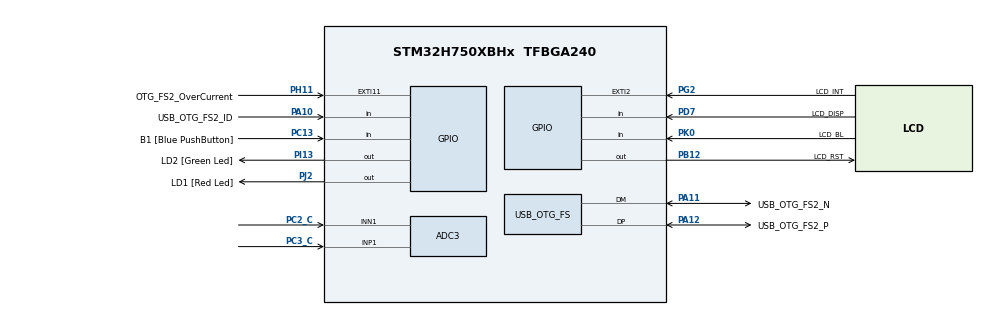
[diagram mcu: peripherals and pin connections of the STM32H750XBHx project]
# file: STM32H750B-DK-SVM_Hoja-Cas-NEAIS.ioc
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ADC3.Channel-0\#ChannelRegularConversion=ADC_CHANNEL_1
ADC3.NbrOfConversionFlag=1
ADC3.OffsetNumber-0\#ChannelRegularConversion=ADC_OFFSET_NONE
ADC3.Rank-0\#ChannelRegularConversion=1
ADC3.SamplingTime-0\#ChannelRegularConversion=ADC_SAMPLETIME_1CYCLE_5
ADC3.SingleDiff-0\#ChannelRegularConversion=ADC_DIFFERENTIAL_ENDED
Mcu.Family=STM32H7
Mcu.Name=STM32H750XBHx
Mcu.Package=TFBGA240
NVIC.OTG_FS_IRQn=true\:0\:0\:false\:false\:true\:false\:true\:true
NVIC.PriorityGroup=NVIC_PRIORITYGROUP_4
PA0_C.Signal=ADCx_INP0
PA1.GPIO_Label=MII_RX_CLK
PA1.Signal=ETH_RX_CLK
PA10.GPIO_Label=USB_OTG_FS2_ID
PA10.Signal=GPIO_Input
PA11.GPIO_Label=USB_OTG_FS2_N
PA11.Mode=Device_Only
PA11.Signal=USB_OTG_FS_DM
PA12.GPIO_Label=USB_OTG_FS2_P
PA12.Mode=Device_Only
PA12.Signal=USB_OTG_FS_DP
PA1_C.Signal=ADCx_INP1
PA2.GPIO_Label=MII_MDIO
PA2.Signal=ETH_MDIO
PA6.Signal=S_TIM13_CH1
PA7.GPIO_Label=MII_RX_DV
PA7.Signal=ETH_RX_DV
PA8.Signal=S_TIM1_CH1
PA9.GPIO_Label=VBUS_FS2
PA9.Signal=USB_OTG_FS_VBUS
PB0.GPIO_Label=MII_RX_D2
PB0.Signal=ETH_RXD2
PB1.GPIO_Label=MII_RX_D3
PB1.Signal=ETH_RXD3
PB10.GPIO_Label=VCP_TX
PB10.Signal=USART3_TX
PB11.GPIO_Label=VCP_RX
PB11.Signal=USART3_RX
PB12.GPIO_Label=LCD_RST
PB12.Signal=GPIO_Output
PB13.GPIO_Label=FDCAN2_TX
PB13.Signal=FDCAN2_TX
PB15.Signal=SPI2_MOSI
PB4\ (NJTRST).Signal=SPI2_NSS
PB5.GPIO_Label=FDCAN2_RX
PB5.Signal=FDCAN2_RX
PB6.Signal=QUADSPI_BK1_NCS
PB8.GPIO_Label=SDIO1_D4
PB8.Signal=SDMMC1_D4
PB9.GPIO_Label=SDIO1_D5
PB9.Signal=SDMMC1_D5
PC0.Signal=ADCx_INP10
PC1.GPIO_Label=MII_MDC
PC1.Signal=ETH_MDC
PC10.GPIO_Label=SDIO1_D2
PC10.Signal=SDMMC1_D2
PC11.GPIO_Label=SDIO1_D3
PC11.Signal=SDMMC1_D3
PC12.GPIO_Label=SDIO1_CK
PC12.Signal=SDMMC1_CK
PC13.GPIO_Label=B1 [Blue PushButton]
PC13.Signal=GPIO_Input
PC14-OSC32_IN\ (OSC32_IN).GPIO_Label=OSC32_IN
PC14-OSC32_IN\ (OSC32_IN).Mode=LSE-External-Clock-Source
PC14-OSC32_IN\ (OSC32_IN).Signal=RCC_OSC32_IN
PC15-OSC32_OUT\ (OSC32_OUT).GPIO_Label=OSC32_OUT
PC15-OSC32_OUT\ (OSC32_OUT).Signal=RCC_OSC32_OUT
PC2.GPIO_Label=MII_TXD2
PC2.Signal=ETH_TXD2
PC2_C.Signal=SharedAnalog_PC2
PC3.GPIO_Label=MII_TX_CLK
PC3.Signal=ETH_TX_CLK
PC3_C.Mode=IN1-Differential
PC3_C.Signal=ADC3_INP1
PC4.GPIO_Label=MII_RXD0
PC4.Signal=ETH_RXD0
PC5.GPIO_Label=MII_RXD1
PC5.Signal=ETH_RXD1
PC6.GPIO_Label=SDIO1_D6
PC6.Signal=SDMMC1_D6
PC7.GPIO_Label=SDIO1_D7
PC7.Signal=SDMMC1_D7
PC8.GPIO_Label=SDIO1_D0
PC8.Signal=SDMMC1_D0
PC9.GPIO_Label=SDIO1_D1
PC9.Signal=SDMMC1_D1
PD0.Signal=FMC_D2_DA2
PD1.Signal=FMC_D3_DA3
PD10.Signal=FMC_D15_DA15
PD11.Signal=QUADSPI_BK1_IO0
PD14.Signal=FMC_D0_DA0
PD15.Signal=FMC_D1_DA1
PD2.GPIO_Label=SDIO1_CMD
PD2.Signal=SDMMC1_CMD
PD3.Signal=SPI2_SCK
PD7.GPIO_Label=LCD_DISP
PD7.Signal=GPIO_Input
PD8.Signal=FMC_D13_DA13
PD9.Signal=FMC_D14_DA14
PE0.Signal=FMC_NBL0
PE1.Signal=FMC_NBL1
PE10.Signal=FMC_D7_DA7
PE11.Signal=FMC_D8_DA8
PE12.Signal=FMC_D9_DA9
PE13.Signal=FMC_D10_DA10
PE14.Signal=FMC_D11_DA11
PE15.Signal=FMC_D12_DA12
PE2.GPIO_Label=MII_TXD3
PE2.Signal=ETH_TXD3
PE4.Signal=SAI4_D2
PE5.Signal=SAI4_CK2
PE7.Signal=FMC_D4_DA4
PE8.Signal=FMC_D5_DA5
PE9.Signal=FMC_D6_DA6
PF0.Signal=FMC_A0
PF1.Signal=FMC_A1
PF10.Signal=QUADSPI_CLK
PF11.Signal=FMC_SDNRAS
PF12.Signal=FMC_A6
PF13.Signal=FMC_A7
PF14.Signal=FMC_A8
PF15.Signal=FMC_A9
PF2.Signal=FMC_A2
PF3.Signal=FMC_A3
PF4.Signal=FMC_A4
PF5.Signal=FMC_A5
PF6.Signal=QUADSPI_BK1_IO3
PF7.Signal=QUADSPI_BK1_IO2
PF8.Signal=ADC3_INP7
PF9.Signal=QUADSPI_BK1_IO1
PG0.Signal=FMC_A10
PG1.Signal=FMC_A11
PG10.Signal=SAI2_SD_B
PG11.GPIO_Label=MII_TX_EN
PG11.Signal=ETH_TX_EN
PG12.GPIO_Label=MII_TXD1
PG12.Signal=ETH_TXD1
PG13.GPIO_Label=MII_TXD0
PG13.Signal=ETH_TXD0
PG15.Signal=FMC_SDNCAS
PG2.GPIO_Label=LCD_INT
PG2.Signal=GPXTI2
PG4.Signal=FMC_A14_BA0
PG5.Signal=FMC_A15_BA1
PG8.Signal=FMC_SDCLK
PH0-OSC_IN\ (PH0).GPIO_Label=OSC_IN
PH0-OSC_IN\ (PH0).Mode=HSE-External-Clock-Source
PH0-OSC_IN\ (PH0).Signal=RCC_OSC_IN
PH1-OSC_OUT\ (PH1).GPIO_Label=OSC_OUT
PH1-OSC_OUT\ (PH1).Signal=RCC_OSC_OUT
PH11.GPIO_Label=OTG_FS2_OverCurrent
PH11.Signal=GPXTI11
PH13.GPIO_Label=FDCAN1_TX
PH13.Signal=FDCAN1_TX
PH14.GPIO_Label=FDCAN1_RX
PH14.Signal=FDCAN1_RX
PH15.Signal=TIM8_CH3N
PH2.GPIO_Label=MII_CRS
PH2.Signal=ETH_CRS
PH3.GPIO_Label=MII_COL
PH3.Signal=ETH_COL
PH5.Signal=FMC_SDNWE
PH6.Signal=FMC_SDNE1
PH7.Signal=FMC_SDCKE1
PH9.Signal=LTDC_R3
PI0.Signal=LTDC_G5
PI1.Signal=LTDC_G6
PI10.GPIO_Label=MII_RX_ER
PI10.Signal=ETH_RX_ER
PI12.Signal=LTDC_HSYNC
PI13.GPIO_Label=LD2 [Green Led]
PI13.Signal=GPIO_Output
PI14.Signal=LTDC_CLK
PI15.Signal=LTDC_R0
PI2.Signal=SPI2_MISO
PI4.Signal=SAI2_MCLK_A
PI5.Signal=SAI2_SCK_A
PI6.Signal=SAI2_SD_A
PI7.Signal=SAI2_FS_A
PI9.Signal=LTDC_VSYNC
PJ0.Signal=LTDC_R1
PJ1.Signal=LTDC_R2
PJ10.Signal=LTDC_G3
PJ11.Signal=LTDC_G4
PJ12.Signal=LTDC_B0
PJ13.Signal=LTDC_B1
PJ14.Signal=LTDC_B2
PJ15.GPIO_Label=LCD_DISP
PJ15.Signal=LTDC_B3
PJ2.GPIO_Label=LD1 [Red Led]
PJ2.Signal=GPIO_Output
PJ3.Signal=LTDC_R4
PJ4.Signal=LTDC_R5
PJ5.Signal=LTDC_R6
PJ6.Signal=LTDC_R7
PJ7.Signal=LTDC_G0
PJ8.Signal=LTDC_G1
PJ9.Signal=LTDC_G2
PK0.GPIO_Label=LCD_BL
PK0.Signal=GPIO_Input
PK2.Signal=LTDC_G7
PK3.Signal=LTDC_B4
PK4.Signal=LTDC_B5
PK5.Signal=LTDC_B6
PK6.Signal=LTDC_B7
PK7.Signal=LTDC_DE
ProjectManager.HeapSize=0x200
ProjectManager.StackSize=0x400
ProjectManager.TargetToolchain=STM32CubeIDE
RCC.ADCFreq_Value=37500000
RCC.APB1Freq_Value=64000000
RCC.APB2Freq_Value=64000000
RCC.APB3Freq_Value=64000000
RCC.APB4Freq_Value=64000000
RCC.CortexFreq_Value=64000000
RCC.DIVM1=22
RCC.DIVM2=2
RCC.DIVN1=169
RCC.DIVN2=12
RCC.DIVP2=4
RCC.DIVQ1=4
RCC.HCLKFreq_Value=64000000
RCC.PLL2FRACN=0
RCC.PLL3FRACN=0
RCC.PLLFRACN=0
RCC.PLLSourceVirtual=RCC_PLLSOURCE_HSE
RCC.SYSCLKFreq_VALUE=64000000
RCC.USBFreq_Value=48011363.63636364
SH.ADCx_INP0.0=ADC1_INP0
SH.ADCx_INP0.1=ADC2_INP0
SH.ADCx_INP1.0=ADC1_INP1
SH.ADCx_INP1.1=ADC2_INP1
SH.ADCx_INP10.0=ADC1_INP10
SH.ADCx_INP10.1=ADC3_INP10
SH.FMC_A0.0=FMC_A0
SH.FMC_A1.0=FMC_A1
SH.FMC_A10.0=FMC_A10
SH.FMC_A11.0=FMC_A11
SH.FMC_A14_BA0.0=FMC_BA0
SH.FMC_A15_BA1.0=FMC_BA1
SH.FMC_A2.0=FMC_A2
SH.FMC_A3.0=FMC_A3
SH.FMC_A4.0=FMC_A4
SH.FMC_A5.0=FMC_A5
SH.FMC_A6.0=FMC_A6
SH.FMC_A7.0=FMC_A7
SH.FMC_A8.0=FMC_A8
SH.FMC_A9.0=FMC_A9
SH.FMC_D0_DA0.0=FMC_D0
SH.FMC_D10_DA10.0=FMC_D10
SH.FMC_D11_DA11.0=FMC_D11
SH.FMC_D12_DA12.0=FMC_D12
SH.FMC_D13_DA13.0=FMC_D13
SH.FMC_D14_DA14.0=FMC_D14
SH.FMC_D15_DA15.0=FMC_D15
SH.FMC_D1_DA1.0=FMC_D1
SH.FMC_D2_DA2.0=FMC_D2
SH.FMC_D3_DA3.0=FMC_D3
SH.FMC_D4_DA4.0=FMC_D4
SH.FMC_D5_DA5.0=FMC_D5
SH.FMC_D6_DA6.0=FMC_D6
SH.FMC_D7_DA7.0=FMC_D7
SH.FMC_D8_DA8.0=FMC_D8
SH.FMC_D9_DA9.0=FMC_D9
SH.FMC_NBL0.0=FMC_NBL0
SH.FMC_NBL1.0=FMC_NBL1
SH.FMC_SDCLK.0=FMC_SDCLK
SH.FMC_SDNCAS.0=FMC_SDNCAS
SH.FMC_SDNRAS.0=FMC_SDNRAS
SH.FMC_SDNWE.0=FMC_SDNWE
SH.S_TIM13_CH1.0=TIM13_CH1
SH.S_TIM1_CH1.0=TIM1_CH1
SH.SharedAnalog_PC2.0=ADC3_INP0
SH.SharedAnalog_PC2.1=ADC3_INN1,IN1-Differential
TIM16.Prescaler=64000 - 1
USB_DEVICE.CLASS_NAME_FS=CDC
USB_DEVICE.VirtualMode-CDC_FS=Cdc
USB_DEVICE.VirtualModeFS=Cdc_FS
USB_OTG_FS.VirtualMode=Device_Only
VP_TIM16_VS_ClockSourceINT.Mode=Enable_Timer
VP_USB_DEVICE_VS_USB_DEVICE_CDC_FS.Mode=CDC_FS
board=STM32H750B-DK

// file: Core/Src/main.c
/* USER CODE BEGIN Header */
/**
  ******************************************************************************
  * @file           : main.c
  * @brief          : Main program body
  ******************************************************************************
  * @attention
  *
  * Copyright (c) 2023 STMicroelectronics.
  * All rights reserved.
  *
  * This software is licensed under terms that can be found in the LICENSE file
  * in the root directory of this software component.
  * If no LICENSE file comes with this software, it is provided AS-IS.
  *
  ******************************************************************************
  */
/* USER CODE END Header */
#include "main.h"
#include "usb_device.h"

/* USER CODE BEGIN Includes */

#include "NanoEdgeAI.h"
#include "knowledge.h"

/* USER CODE END Includes */

/* USER CODE BEGIN PD */

#define SIGNAL_SIZE (uint32_t)(DATA_INPUT_USER * AXIS_NUMBER)

uint16_t id_class = 0; // Point to id class (see argument of neai_classification fct)
float input_user_buffer[DATA_INPUT_USER * AXIS_NUMBER]; // Buffer of input values
float output_class_buffer[CLASS_NUMBER]; // Buffer of class probabilities
const char *id2class[CLASS_NUMBER + 1] = { // Buffer for mapping class id to class name
	"unknown",
	"Jaz",
	"Mami",
	"Mirovanje",
	"Sestra",
	"Vati",
};

#define BUFSIZE 256
char	SendBuffer[BUFSIZE];

int counterOfTestData = 0;

int numberOfDurations = 100;
uint32_t averageDurationValue = 0;
int countDurations = 0;

float testData[][16] = {{-0.0006153846153846, 0.0009126008090542, 0.005, 0.001100699078558, 0.0215576923076923, 0.0014730066261595, 0.007, 0.0216079579357663, 0.99125, 0.0013850159676946, 0.007, 0.991250967600653, 0.9914860865289108, 0.0013915363564239, 0.0069986197331466, 0.9914870630289868},
		 {-0.0008076923076923, 0.0011525633895208, 0.006, 0.0014073980356563, 0.022125, 0.0014589742181514, 0.007, 0.022173051904716, 0.9918365384615384, 0.0013875169917398, 0.007, 0.9918375089856046, 0.9920853495423456, 0.0013886879458306, 0.0069986197331466, 0.9920863214613784},
		 {-0.0010961538461538, 0.0010698600804385, 0.006, 0.001531715980903, 0.0219134615384615, 0.0014878390171078, 0.007, 0.0219639127101357, 0.9917115384615384, 0.0014456371826655, 0.007, 0.9917125921276866, 0.9919559117196474, 0.0014471366359818, 0.006999781054934, 0.9919569673125946},
		 {-0.0007596153846153, 0.0009756180714305, 0.005, 0.0012364651850521, 0.0213173076923076, 0.0014693301919642, 0.0089999999999999, 0.0213678856806549, 0.9916826923076922, 0.0013746637566281, 0.007, 0.9916836450819771, 0.9919136446624848, 0.001374350784471, 0.0069977714978647, 0.9919145967812412},
		 {-0.0006153846153846, 0.0010946345746736, 0.006, 0.0012557559782549, 0.0210961538461538, 0.0013624019426198, 0.0089999999999999, 0.0211401004291334, 0.9916538461538462, 0.0012991804426195, 0.007, 0.9916546971912846, 0.9918799490453064, 0.0012984269903886, 0.0070407384599673, 0.991880798902151},
		 {-0.0007788461538461, 0.0011925790634105, 0.006, 0.0014243757067031, 0.0213942307692307, 0.001281662601338, 0.006, 0.0214325866201625, 0.9917211538461538, 0.001281951117882, 0.007, 0.9917219824046531, 0.9919537421015062, 0.0012839512523174, 0.0070604515117855, 0.9919545730526173},
		 {-0.0005192307692307, 0.0011092337031861, 0.006, 0.0012247448713915, 0.0217211538461538, 0.0013619607667541, 0.008, 0.02176381082298, 0.9916634615384616, 0.0012216837130266, 0.006, 0.9916642140672104, 0.9919030045192532, 0.0012274154778763, 0.0061069144012922, 0.991903763942388},
		 {-0.000701923076923, 0.0010820191923179, 0.006, 0.0012897525105467, 0.0215288461538461, 0.0017150730572532, 0.0089999999999999, 0.0215970528616219, 0.9916634615384616, 0.0012058397721973, 0.006, 0.9916641946747902, 0.9918994351241432, 0.0012172732855579, 0.0061428032735051, 0.991900182051524},
		 {-0.0010096153846153, 0.0010515116619172, 0.005, 0.0014577379737113, 0.0213557692307692, 0.0016344739757838, 0.008, 0.0214182255244309, 0.991778846153846, 0.0012931530545473, 0.007, 0.9917796892067698, 0.9920111520474486, 0.0013005849398878, 0.0070561887258223, 0.9920120046187406},
		 {-0.000875, 0.0013059589756779, 0.007, 0.0015719904090527, 0.0213461538461538, 0.0012616322666812, 0.006, 0.021383404780343, 0.9917115384615384, 0.0015296623365649, 0.008, 0.9917127181722616, 0.9919432905184492, 0.0015313176982252, 0.0079998762148856, 0.9919444725076406},
		 {-0.0007403846153846, 0.0015504043660364, 0.008, 0.0017181161418609, 0.0216153846153846, 0.0015523412362008, 0.008, 0.0216710547824653, 0.9917115384615384, 0.0018010310984964, 0.009, 0.9917131738717446, 0.9919497674007284, 0.0018068544135016, 0.0090195625065186, 0.9919514130083342},
		 {-0.0008365384615384, 0.0014683230683797, 0.008, 0.0016899021364473, 0.0215384615384615, 0.0015988161300635, 0.008, 0.0215977206774589, 0.9915865384615384, 0.0017187348708317, 0.009, 0.9915880280175292, 0.9918231541494058, 0.0017220651870083, 0.0090175529494493, 0.9918246491267418},
		 {-0.0009038461538461, 0.0011310243040409, 0.006, 0.001447810017286, 0.0218365384615384, 0.0015386718606234, 0.007, 0.0218906811926199, 0.9912692307692308, 0.001710998186118, 0.011, 0.991270707417815, 0.991511987995242, 0.0017003303389435, 0.0110206531330633, 0.9915134459307844},
		 {-0.0005, 0.001263389823512, 0.007, 0.0013587324409735, 0.0219423076923076, 0.00157398882728, 0.007, 0.0219986887721133, 0.9914134615384615, 0.0016208412875078, 0.012, 0.9914147864774632, 0.991658443727564, 0.0016119216847919, 0.0119962476913922, 0.991659753800512},
		 {-0.0005096153846153, 0.0013300895885651, 0.007, 0.0014243757067031, 0.0216442307692307, 0.0015622854882336, 0.007, 0.0217005405817104, 0.9916346153846154, 0.001308681752373, 0.008, 0.991635478932114, 0.991873053305952, 0.0013082469734078, 0.0080424146674693, 0.9918739160723076},
		 {-0.000826923076923, 0.0011132273568004, 0.005, 0.001386750490563, 0.0216057692307692, 0.0015530260116622, 0.005, 0.0216615131938226, 0.991548076923077, 0.0014133961261682, 0.008, 0.991549084280986, 0.9917856321416704, 0.0014109027527474, 0.0079821274380095, 0.9917866357081198},
		 {-0.0006057692307692, 0.0011130197077421, 0.005, 0.0012671895007335, 0.0215480769230769, 0.0015246677298318, 0.006, 0.0216019496983311, 0.9916153846153848, 0.0013031595650844, 0.007, 0.9916162409071207, 0.991851469449978, 0.0012968348734568, 0.0069373241897775, 0.9918523172482732},
		 {-0.000576923076923, 0.0012379597645716, 0.007, 0.0013657908388126, 0.0215288461538461, 0.0016405717270866, 0.007, 0.0215912642591325, 0.9916538461538462, 0.0013138992963491, 0.007, 0.9916547165838908, 0.9918898087278836, 0.0013161845471892, 0.0070056494405842, 0.9918906819806304},
		 {-0.000826923076923, 0.0013188158127384, 0.007, 0.0015566235649883, 0.0214230769230769, 0.0014052943004957, 0.007, 0.0214691191464176, 0.9917019230769232, 0.0021567417006479, 0.013, 0.9917042683024162, 0.9919354998104336, 0.0021601247422605, 0.0130394307567965, 0.9919378518451026},
		 {-0.0006346153846153, 0.0012561976533884, 0.007, 0.0014073980356563, 0.0215576923076923, 0.0012847247765491, 0.006, 0.0215959397893357, 0.9920288461538462, 0.0022380311177514, 0.013, 0.9920313706655728, 0.992264886130281, 0.0022364083015845, 0.0130394307567965, 0.9922674063825894},
		 {-0.0005673076923076, 0.0011582847321406, 0.007, 0.0012897525105467, 0.0217596153846153, 0.0015031709580064, 0.007, 0.0218114736919673, 0.9920384615384616, 0.0023325583384701, 0.0149999999999999, 0.9920412037813752, 0.9922790465078032, 0.0023340325016292, 0.0149966500112984, 0.9922817915522556},
		 {-0.000701923076923, 0.0012079847147236, 0.006, 0.0013971124066885, 0.0215096153846153, 0.0014741046324652, 0.007, 0.0215600681460318, 0.9917211538461538, 0.0026181934860085, 0.0159999999999999, 0.9917246099210592, 0.9919564656135036, 0.0026192961232579, 0.0159746008416751, 0.9919599237794918},
		 {-0.0008076923076923, 0.0012639751327042, 0.006, 0.0015, 0.0212499999999999, 0.0013569621047937, 0.007, 0.0212932817140488, 0.9915673076923076, 0.0019988670977721, 0.012, 0.9915693224146488, 0.9917970576620968, 0.0019928403868917, 0.0119754843190796, 0.9917990597898346},
		 {-0.0010384615384615, 0.0012162606385263, 0.006, 0.0015992786835609, 0.0215192307692307, 0.0015062738618012, 0.007, 0.0215718834098034, 0.9918076923076924, 0.0014876215081395, 0.009, 0.9918088079556772, 0.9920435584637732, 0.0014810452894739, 0.008917480333952, 0.9920446640069264},
		 {-0.0011442307692307, 0.0014034180063657, 0.009, 0.0018107584471282, 0.0216634615384615, 0.0015787688540994, 0.007, 0.0217209133537951, 0.991875, 0.0014120872439815, 0.007, 0.9918760051616252, 0.9921144624235309, 0.0014071206524204, 0.0069179759786354, 0.9921154602859796},
		 {-0.0008942307692307, 0.0013581539311107, 0.009, 0.0016261090889699, 0.0216923076923076, 0.001635407048113, 0.009, 0.021753867914253, 0.9915576923076924, 0.001328872592412, 0.006, 0.9915585827760874, 0.9917976290602484, 0.0013270521440798, 0.0060447438028601, 0.9917985168757428},
		 {-0.0008173076923076, 0.0011990735452272, 0.006, 0.0014511268830702, 0.021826923076923, 0.0015898857463322, 0.008, 0.0218847505741396, 0.9915673076923076, 0.0012385197669063, 0.007, 0.9915680811802003, 0.991809846813995, 0.0012391348220779, 0.0070217288578864, 0.9918106208809764},
		 {-0.0008557692307692, 0.0011882296886121, 0.006, 0.0014643192169847, 0.0217307692307692, 0.0014756404687116, 0.007, 0.0217808137165223, 0.9917788461538464, 0.0013933684335867, 0.007, 0.9917798249378972, 0.9920190615246436, 0.0013967113282921, 0.0070200191501373, 0.9920200447726696},
		 {-0.0008365384615384, 0.0011103583701036, 0.006, 0.0013902130439944, 0.0218461538461538, 0.0015365372581106, 0.008, 0.0219001229360792, 0.9918365384615384, 0.0014149651865999, 0.007, 0.9918375477636678, 0.992079253095979, 0.0014229572353826, 0.007022531090768, 0.9920802735821176},
		 {-0.001076923076923, 0.001174179809421, 0.006, 0.0015932550136313, 0.021826923076923, 0.0014239861959971, 0.0069999999999999, 0.0218733241116275, 0.991875, 0.0014589742181514, 0.007, 0.9918760730206012, 0.9921174260223224, 0.001462184270762, 0.0070240489646161, 0.9921185035065117},
		 {-0.0010961538461538, 0.0011971057305758, 0.005, 0.0016231498343083, 0.0216057692307692, 0.0015836804093797, 0.008, 0.0216637325429462, 0.9916153846153846, 0.0014696133211186, 0.007, 0.9916164736273952, 0.9918533300649374, 0.0014677640824998, 0.0070195274669162, 0.991854416077434},
		 {-0.0009038461538461, 0.0013120684694935, 0.006, 0.0015932550136313, 0.0214326923076923, 0.0017692046402752, 0.008, 0.0215055896132932, 0.9916923076923077, 0.0015816065534578, 0.008, 0.9916935689089572, 0.991926738730617, 0.0015838095783742, 0.0080483800416394, 0.9919280031643116},
		 {-0.0007980769230769, 0.0012813740198311, 0.006, 0.0015095847620607, 0.0212692307692307, 0.0014089737756934, 0.007, 0.021315848203048, 0.9920192307692308, 0.001720804648719, 0.009, 0.9920207232636904, 0.9922493570092754, 0.0017242766785224, 0.0090501778329528, 0.9922508551850104},
		 {-0.000951923076923, 0.0011716179451798, 0.006, 0.0015095847620607, 0.0212499999999999, 0.001371060790887, 0.008, 0.0212941848327731, 0.9918076923076924, 0.0015259103403751, 0.009, 0.991808866124455, 0.992037411656712, 0.0015237947284188, 0.0089999895497346, 0.9920385819497765},
		 {-0.0011442307692307, 0.0012043053314508, 0.005, 0.0016612090129226, 0.0212596153846153, 0.0015190786194502, 0.008, 0.0213138181974475, 0.9917403846153848, 0.0015565938672163, 0.008, 0.9917416061966636, 0.9919707832875176, 0.0015546790747756, 0.0079975273944218, 0.9919720015822407},
		 {-0.0008653846153846, 0.0012173244013921, 0.006, 0.0014935759876113, 0.0216923076923076, 0.0014079234782863, 0.006, 0.0217379498007162, 0.9917692307692308, 0.0025952277550518, 0.0159999999999999, 0.9917726263149697, 0.9920085492459444, 0.0025980302958407, 0.0160185381325039, 0.99201195130828},
		 {-0.0005384615384615, 0.0009992600812897, 0.005, 0.0011351041971825, 0.0217211538461538, 0.0013829784661627, 0.007, 0.0217651362009557, 0.9918653846153844, 0.0025459533967111, 0.0159999999999999, 0.9918686521293648, 0.992104798177164, 0.00254992669627, 0.0160185381325039, 0.9921080751068948},
		 {-0.0005384615384615, 0.0010183232534518, 0.004, 0.0011519214716824, 0.0215673076923076, 0.0013711619376177, 0.006, 0.021610850195072, 0.9919230769230768, 0.0017688126596256, 0.009, 0.991924654008947, 0.9921591379428876, 0.0017663511616563, 0.00897811230925, 0.9921607102682508},
		 {-0.0006538461538461, 0.001081036101735, 0.005, 0.001263389823512, 0.0216826923076923, 0.0014823605335677, 0.008, 0.0217333048214379, 0.991721153846154, 0.0025055965463846, 0.014, 0.991724319052427, 0.99196007940433, 0.0025017115067559, 0.0140430924130311, 0.991963234042627},
		 {-0.0009038461538461, 0.0012443660014489, 0.006, 0.001537980694087, 0.0217692307692307, 0.0015078689064548, 0.008, 0.021821390352658, 0.9916346153846154, 0.0022789070098982, 0.014, 0.9916372339954536, 0.9918758736078112, 0.002278960823201, 0.0140430924130311, 0.9918784917053562},
		 {-1.0209326923076925, 0.1302167766887701, 0.5049999999999999, 1.0292035615726591, 0.0355480769230769, 0.1076365751220006, 0.788, 0.1133547443952968, -0.127326923076923, 0.1539804834228933, 0.833, 0.1998052417114841, 1.0462381311776645, 0.1319741516965437, 0.482384070452336, 1.054528996209281},
		 {-1.0039519230769232, 0.2195937411452064, 0.8930000000000001, 1.0276871484065566, 0.0742403846153846, 0.1601154328308839, 0.859, 0.1764896216168575, 0.001201923076923, 0.2776807581699536, 1.417, 0.2776833593806497, 1.051955374307347, 0.2403900997987924, 1.1131224831140258, 1.079072522871093},
		 {-0.9404326923076924, 0.2366166066585303, 1.171, 0.9697427840967378, 0.0566057692307692, 0.1825326323970399, 0.813, 0.1911082808252955, -0.0380865384615384, 0.2898907987560184, 1.616, 0.2923820439346175, 1.0036213029257648, 0.2348509787858408, 1.1131224831140258, 1.0307330895644502},
		 {-0.961076923076923, 0.2794430481507159, 1.212, 1.0008782489547714, 0.0176346153846153, 0.1576397461651277, 0.777, 0.1586230412984483, -0.0903942307692307, 0.2747196269440071, 1.338, 0.2892092501712477, 1.018126919725353, 0.271989161873627, 0.9959925341562422, 1.0538313569286852},
		 {-0.9754615384615384, 0.2703303507205767, 1.1510000000000002, 1.0122271047242617, 0.0561730769230769, 0.1978418872536122, 1.054, 0.2056619238533883, -0.02, 0.336765811118738, 1.718, 0.3373591728980576, 1.0426529897471382, 0.3059190954670111, 1.4012503450985978, 1.0866056092253529},
		 {-1.031875, 0.2632812435802327, 1.205, 1.064933344790252, 0.032, 0.2107283157929258, 1.054, 0.213144136857956, -0.0714038461538461, 0.3143646375943428, 1.701, 0.3223718886866294, 1.0959972504701725, 0.2867527044341235, 1.4047466931979975, 1.1328888235561607},
		 {-1.017048076923077, 0.3082716515512705, 1.3119999999999998, 1.0627408912444636, 0.0387884615384615, 0.2009094071139126, 0.981, 0.2046194873793418, -0.0161730769230769, 0.3592355784351119, 1.759, 0.359599456660837, 1.0940278675842678, 0.322028152058559, 1.3789372915071472, 1.1404381200964964},
		 {-1.0466826923076922, 0.2873516093442866, 1.418, 1.0854103398112764, 0.0479711538461538, 0.2005265883354072, 0.981, 0.2061847332630843, -0.004, 0.3550846865402458, 1.743, 0.3551072156622343, 1.1207014336857417, 0.3012593254160075, 1.3789372915071472, 1.1604864861838695},
		 {-1.0026826923076924, 0.3402947326731038, 1.46, 1.058854610670635, 0.0680961538461538, 0.1851279972608748, 0.899, 0.1972548137269697, -0.0231057692307692, 0.3699489548538895, 1.868, 0.3706698069296051, 1.082749710999199, 0.3537396177660977, 1.451811274290198, 1.1390692050293318},
		 {-0.9995096153846156, 0.3375844337459066, 1.44, 1.0549799624418683, 0.0448942307692307, 0.2025184663122975, 1.049, 0.2074348600256142, 0.0119326923076923, 0.3529688443546528, 1.868, 0.3531704889012801, 1.0756343984353505, 0.3517839925878995, 1.451811274290198, 1.1316984300326929},
		 {-1.0267211538461538, 0.3113768572723774, 1.244, 1.0728988186217747, 0.0731923076923077, 0.2002552254635164, 1.049, 0.2132117943050272, -0.0049134615384615, 0.3372758261359833, 1.577, 0.3373116140899984, 1.093863170740102, 0.3373627616219365, 1.2751706729677297, 1.1447053198228658},
		 {-0.968721153846154, 0.3167383188523893, 1.632, 1.0191878318241745, 0.0695192307692307, 0.2368694455719482, 1.25, 0.2468604012236626, -0.0029903846153846, 0.3153412832274651, 1.541, 0.3153554618326632, 1.0432276584705622, 0.3328798794467598, 1.4329995112709926, 1.0950492963964964},
		 {-1.0007307692307692, 0.2964830787352481, 1.632, 1.0437261558768844, -0.0135384615384615, 0.2667286478757637, 1.146, 0.2670720156408408, -0.0558942307692307, 0.2628258387319966, 1.478, 0.2687035290770509, 1.0695491103416352, 0.2982583395412068, 1.4329995112709926, 1.1103573012947054},
		 {-0.9846346153846156, 0.3197319206921127, 1.908, 1.0352457809250308, 0.0307884615384615, 0.2867343206456016, 1.402, 0.2883825584185008, -0.0837884615384615, 0.3144560833064012, 1.986, 0.3254276180894679, 1.082947981126827, 0.2966902959515042, 1.316523074420104, 1.1228541586236664},
		 {-1.0020865384615385, 0.3370748921170339, 1.856, 1.0572591515146788, 0.0039711538461538, 0.2619194112967827, 1.402, 0.2619495143666486, -0.119701923076923, 0.2666502275312279, 1.848, 0.2922856380850233, 1.085139781819275, 0.3071107449804504, 1.3071311234186074, 1.1277612139851374},
		 {-1.011375, 0.3186513101368376, 1.5710000000000002, 1.0603858015255216, 0.014576923076923, 0.287124594112693, 1.298, 0.2874943812159974, -0.0527596153846153, 0.3431943689916027, 1.861, 0.3472260818588905, 1.0996873195991497, 0.3439837472085079, 1.552717958972016, 1.1522313219274891},
		 {-1.0558269230769233, 0.273499593668229, 1.419, 1.0906752583747232, -0.0087403846153846, 0.3066470344772605, 1.391, 0.3067715731239175, -0.0451346153846153, 0.353006157543057, 1.886, 0.3558798684517442, 1.147994925176817, 0.3040385663780137, 1.552717958972016, 1.187573912679511},
		 {-1.0162307692307693, 0.2788153935288349, 1.2919999999999998, 1.053785082452774, 0.0209326923076923, 0.2783682281972469, 1.339, 0.2791541654300058, -0.057875, 0.3264011715046614, 1.74, 0.3314924439329129, 1.1006319004491325, 0.2947655138839511, 1.3429595052505432, 1.1394197156717705},
		 {-1.0259326923076924, 0.2704723881976991, 1.293, 1.0609868999771284, 0.0727403846153846, 0.2209456509569155, 0.874, 0.2326115737248884, -0.052451923076923, 0.3081734925894233, 1.677, 0.3126053514724768, 1.095894952047438, 0.2766544884870294, 1.3429595052505432, 1.1302758300180875},
		 {-1.0027403846153846, 0.3537332489970456, 1.628, 1.0633040441870871, 0.0732980769230769, 0.2074925336843793, 1.041, 0.220058536792792, -0.0450673076923077, 0.3470273283525675, 1.681, 0.3499414648854203, 1.080361187278459, 0.3664969084022837, 1.6522725558472875, 1.1408331511865148},
		 {-0.981971153846154, 0.3478366508957343, 1.628, 1.0417570171073038, 0.0455, 0.2180174657788118, 1.145, 0.2227147623859167, -0.0124807692307692, 0.3305792986669016, 1.649, 0.3308148157318416, 1.0551097115205432, 0.3619965290436518, 1.6522725558472875, 1.1154810578331733},
		 {-1.0034615384615384, 0.3159437304780748, 1.182, 1.0520244769015594, 0.0523846153846153, 0.1759290890634582, 1.173, 0.1835625024554097, -0.0120865384615384, 0.3288542496473091, 1.618, 0.3290762858716455, 1.0661866285586663, 0.3346460328667794, 1.24755568711768, 1.1174712051013973},
		 {-0.9653846153846154, 0.3519447975642549, 1.871, 1.0275371507414446, 0.0515576923076923, 0.2077501655522378, 1.208, 0.2140521593515863, -0.0835096153846153, 0.3342696399843047, 1.618, 0.3445432455830807, 1.042119532125935, 0.366534925914937, 1.7731409884280809, 1.104699493597171},
		 {-0.9936730769230768, 0.3354203861261179, 1.871, 1.0487578458494455, 0.0104134615384615, 0.2373547171257902, 1.255, 0.2375830421622657, -0.1218653846153846, 0.2143827480184191, 1.01, 0.2465991374992714, 1.051587037897014, 0.3336383633460258, 1.7731409884280809, 1.103245147630041},
		 {-0.9785288461538462, 0.3235225873915371, 1.3769999999999998, 1.030623872859392, 0.0696923076923076, 0.2603753975189209, 1.249, 0.269541027275284, 0.0131538461538461, 0.3500016969527755, 1.86, 0.3502487852062609, 1.0698469458478956, 0.3360649590342603, 1.4287109436303491, 1.1213884894320831},
		 {-1.0561057692307694, 0.2946499526253153, 1.491, 1.0964387763959351, 0.0201634615384615, 0.2361579943180527, 1.249, 0.2370172218669741, -0.024875, 0.3487221090997816, 1.86, 0.349608173531455, 1.1359808292088214, 0.3002142310354264, 1.2490234714237065, 1.17498128872172},
		 {-1.012596153846154, 0.3245518957919214, 1.273, 1.0633366841439047, 0.0414134615384615, 0.2474643179630971, 1.228, 0.2509056863874122, -0.0403365384615384, 0.3579989151943416, 1.914, 0.3602641525539068, 1.0933957303550648, 0.3576515116204479, 1.6536953685560714, 1.1504037669110254},
		 {-1.0139999999999998, 0.3072347198428639, 1.273, 1.0595230875620043, 0.0594615384615384, 0.2349050922540077, 1.192, 0.2423140048017797, -0.0207596153846153, 0.3604206275363526, 2.172, 0.3610179917741156, 1.0931459297867077, 0.3415716858514036, 1.6536953685560714, 1.1452681958321445},
		 {-1.0065865384615384, 0.3504859980352809, 1.856, 1.0658596972541785, 0.0829134615384615, 0.167269307875798, 0.952, 0.1866913588293214, -0.016451923076923, 0.3331023139138533, 1.6909999999999998, 0.3335083466836959, 1.0761917076734684, 0.3520650271396797, 1.660552090417494, 1.1323154926962715},
		 {-0.9287692307692308, 0.3277619102679339, 1.856, 0.9849061649955054, 0.0458557692307692, 0.1829032120185864, 1.027, 0.1885638791986989, -0.0191538461538461, 0.3133842188736587, 1.594, 0.3139690087596839, 0.9981639270250556, 0.3283927581906656, 1.733137242023767, 1.0507963783940986},
		 {-0.972625, 0.275185398605684, 1.431, 1.0108048249938113, 0.0320865384615384, 0.1899776864719868, 1.019, 0.1926682830869998, -0.0858942307692307, 0.2910514730536782, 1.5779999999999998, 0.3034613300671995, 1.032471849596612, 0.2914414523968181, 1.3126237900170925, 1.0728169649966464},
		 {-0.9872403846153848, 0.3606554528587848, 2.253, 1.0510546763571853, 0.0388653846153846, 0.2489611514988258, 1.134, 0.2519765327901054, -0.1080384615384615, 0.3184651871771654, 1.5779999999999998, 0.3362921120326562, 1.068136384568077, 0.3746800693210844, 2.2953959816986584, 1.1319454449683586},
		 {-0.9879711538461536, 0.3585440498828016, 2.253, 1.0510189515600856, 0.0130961538461538, 0.2597974254932088, 1.134, 0.2601272987182651, -0.0859615384615384, 0.2500557600538221, 1.1829999999999998, 0.2644187384259467, 1.0527670635178177, 0.3659314516132269, 2.2953959816986584, 1.1145511730323074},
		 {-0.9539038461538462, 0.2740220204244812, 1.304, 0.9924820478903462, 0.0960865384615384, 0.2432387285149226, 0.974, 0.2615295431171723, 0.0682980769230769, 0.3160262245632257, 1.38, 0.3233221333640443, 1.0398297220294042, 0.2769651032441118, 1.14979467935453, 1.076083416483485},
		 {-1.038634615384615, 0.2409059446887738, 1.256, 1.0662070804780557, 0.0510865384615384, 0.2366171083684211, 0.974, 0.2420691851199061, 0.0346634615384615, 0.3212723685890011, 1.443, 0.3231369529852867, 1.1181560643489552, 0.2225747851631546, 0.986445803302742, 1.140093206378658},
		 {-0.995903846153846, 0.3208867676884087, 1.325, 1.046323462635498, 0.0776730769230769, 0.2011767995067108, 0.8880000000000001, 0.2156506701553731, -0.0306153846153846, 0.358576306322129, 1.94, 0.359880909789293, 1.074786472512573, 0.3400680927913542, 1.531060519250232, 1.1273030955474084},
		 {-0.9744423076923078, 0.3080890176969049, 1.407, 1.021986621167887, 0.0423846153846153, 0.2297095702977795, 1.156, 0.2335871193103171, -0.0107788461538461, 0.3364776811872225, 1.937, 0.3366502836201663, 1.0501716798441765, 0.3308964376789889, 1.531060519250232, 1.101069030358853},
		 {-0.9998557692307694, 0.2568625200325754, 1.113, 1.0323225820747788, 0.0122980769230769, 0.2052437987355006, 1.024, 0.2056119150618091, -0.0106346153846153, 0.3280619388543146, 1.778, 0.3282342620282513, 1.0626498507586912, 0.2940734577085891, 1.2702868335563635, 1.1025896352887383},
		 {-0.9411442307692308, 0.2541597172838231, 1.126, 0.9748587718228728, 0.0630480769230769, 0.2195907198109041, 1.078, 0.2284625663665039, -0.0522115384615384, 0.3395355615530891, 1.778, 0.3435264797765847, 1.0184887518596142, 0.2885062804756714, 1.2702868335563635, 1.0585628047208449},
		 {-0.9938076923076924, 0.2654864576048986, 1.165, 1.0286577606092022, 0.0165480769230769, 0.2167743811062416, 1.078, 0.2174050853909497, -0.1177788461538461, 0.1937399107413164, 0.965, 0.2267311394920967, 1.0427563345245825, 0.2635678205692536, 1.109420751352573, 1.0755504494121926},
		 {-0.9712980769230768, 0.0473239408853189, 0.2719999999999999, 0.972450260741075, -0.1112403846153846, 0.074193418637254, 0.472, 0.1337127014851676, -0.0072596153846153, 0.0396339004059723, 0.204, 0.0402932758276499, 0.98124292957726, 0.0482126268254013, 0.2997925462055116, 0.9824266609934652},
		 {-0.9875, 0.1153747239349976, 0.5700000000000001, 0.9942170673062684, -0.1463365384615384, 0.1930592082644856, 0.887, 0.2422524311221982, -0.0060961538461538, 0.1223326580107549, 0.6930000000000001, 0.1224844574127358, 1.020797371464483, 0.1418766577932656, 0.6613619343045795, 1.030609654338336},
		 {-0.967528846153846, 0.346412103313013, 1.669, 1.027673787474186, -0.153076923076923, 0.3024965254825154, 1.757, 0.3390231442065457, 0.042826923076923, 0.2608180342067159, 1.653, 0.2643107873464349, 1.04149292948331, 0.3952249687370429, 2.2352903797765213, 1.11396153348171},
		 {-0.9864230769230768, 0.4254011385718482, 2.033, 1.0742423448108045, -0.1080576923076923, 0.445022770094258, 2.166, 0.4579538522266526, 0.0393942307692307, 0.4803600496236216, 3.176, 0.4819726991151134, 1.1390587748664935, 0.5464074818720883, 2.7791407186426187, 1.2633352796649644},
		 {-1.0367884615384615, 0.4918925123571386, 2.213, 1.1475576489624857, -0.1483942307692307, 0.5114279108961879, 2.545, 0.5325216951160119, 0.0792211538461538, 0.5243183662317193, 3.176, 0.5302694978825535, 1.2302928582759376, 0.6066573470431041, 2.6797647469455126, 1.3717338130432426},
		 {-1.0204230769230769, 0.4966984399378423, 2.213, 1.1348888034313522, -0.1514903846153846, 0.477382466308005, 2.54, 0.5008426457174256, 0.0804711538461538, 0.5080979795868186, 2.449, 0.5144309122336433, 1.2030360099148536, 0.5967909803547338, 2.415691119314473, 1.342927814658932},
		 {-1.0183846153846154, 0.5345480353261116, 2.576, 1.1501516538800771, -0.1304038461538461, 0.4789068385241612, 2.317, 0.4963435534757383, 0.060701923076923, 0.5159111968868527, 2.449, 0.5194700054271292, 1.1991508215588242, 0.6333183588790541, 2.730988608648211, 1.3561175599993025},
		 {-1.00775, 0.5546327050400112, 2.641, 1.1502945275015437, -0.1273846153846153, 0.4967835255941717, 2.36, 0.5128554489702353, 0.0215192307692307, 0.4233749470434259, 2.268, 0.4239214822074048, 1.175959175930823, 0.6188922775083597, 2.730988608648211, 1.328874574448388},
		 {-0.9787884615384616, 0.4655321535841644, 2.014, 1.083857480696396, -0.0782980769230769, 0.4955023651229685, 2.492, 0.5016504586784584, -0.0023557692307692, 0.3680634852813916, 1.921, 0.3680710241871178, 1.133000552991596, 0.5274336421965687, 2.0942353460303664, 1.2497505751148907},
		 {-0.9990576923076924, 0.4022477907125608, 1.765, 1.076995616375623, -0.0864326923076923, 0.4643267824003801, 2.3840000000000003, 0.4723028383927479, 0.0511346153846153, 0.3676158911379645, 1.662, 0.3711552132298458, 1.1399032933994928, 0.470495699077936, 2.0942353460303664, 1.233185193372774},
		 {-1.0300192307692309, 0.504387632922896, 2.2990000000000004, 1.1468855653464298, -0.1358557692307692, 0.3252738614870798, 1.642, 0.3525051418064707, -0.050201923076923, 0.3406944090837376, 1.6589999999999998, 0.3443732182698568, 1.1355186452960764, 0.5184560681933447, 2.339313807214618, 1.2482785300010324},
		 {-1.043471153846154, 0.5256435425107817, 2.2990000000000004, 1.16838914009516, -0.151451923076923, 0.2640293864693449, 1.359, 0.3043833141338022, -0.0560096153846153, 0.3052099370544399, 1.637, 0.3103065946645473, 1.132423511322605, 0.521238485063674, 2.339313807214618, 1.246624469239912},
		 {-1.031076923076923, 0.4556055077566829, 2.3320000000000003, 1.1272515247272898, -0.0772115384615384, 0.3664605045640327, 1.644, 0.3745062390360447, 0.0152884615384615, 0.3496121937528925, 2.029, 0.3499463145639958, 1.1346733621837712, 0.4959130037662076, 2.436464504229499, 1.2383106824031869},
		 {-1.0263076923076924, 0.42488786024901, 1.939, 1.110782234768329, -0.1460096153846153, 0.3892273780589198, 1.894, 0.4157123520120428, 0.016701923076923, 0.355053486756348, 2.183, 0.3554461037798947, 1.1375864157886555, 0.4887668278409813, 2.436464504229499, 1.2381421022583052},
		 {-1.0204423076923077, 0.4793987184870045, 2.348, 1.1274420759468686, -0.164826923076923, 0.4104168716146025, 1.873, 0.442278106033888, -0.0258653846153846, 0.3668004083571962, 2.199, 0.3677112422707629, 1.1582194000642536, 0.5103674526254747, 2.510681721104558, 1.2656804949846605},
		 {-1.0619423076923078, 0.5126298302142042, 2.348, 1.1791992230714483, -0.1151634615384615, 0.476135527542335, 2.188, 0.4898649441035135, 0.0059326923076923, 0.4040337063343724, 2.137, 0.4040772607958874, 1.222424979252226, 0.5472056961932587, 2.510681721104558, 1.339312100985485},
		 {-1.0059423076923075, 0.528960025153186, 2.291, 1.13653800403479, -0.0946153846153846, 0.4110785370333356, 2.188, 0.4218265456504422, 0.0440480769230769, 0.4127055986416321, 2.066, 0.4150495684020996, 1.1375724257403914, 0.5897892756372061, 2.4873746351325465, 1.281375204013851},
		 {-0.9832211538461538, 0.5306660176088369, 2.291, 1.1172870086129991, -0.0264423076923076, 0.4334395492170088, 2.2960000000000003, 0.4342453666552338, 0.013826923076923, 0.3623320683250192, 1.977, 0.3625957963607156, 1.1019414000698022, 0.5950631566712805, 2.5099524256222425, 1.2523477989821297},
		 {-0.9823365384615385, 0.5800126094547249, 3.487, 1.1407890698648355, -0.119701923076923, 0.5897436353034403, 3.1740000000000004, 0.60176914657469, -0.0032211538461538, 0.4370785433009189, 3.077, 0.4370904126678527, 1.2002226275495271, 0.6434589970282262, 4.045615201135299, 1.3618273886724637},
		 {-0.947721153846154, 0.6478253482692748, 3.487, 1.1479778165573116, -0.2226730769230769, 0.601963764599276, 2.98, 0.641828382885116, 0.045625, 0.4152922786215658, 3.077, 0.417790997159695, 1.1995886866936822, 0.6821532382455089, 4.045615201135299, 1.3799804555472182},
		 {-0.9972211538461538, 0.5530372076217416, 2.76, 1.140307056319616, -0.1174807692307692, 0.601319478326449, 2.722, 0.6126882128406309, 0.0349807692307692, 0.61109181893447, 3.331, 0.6120922033359152, 1.30321012982269, 0.5932851352918733, 2.6018581959227483, 1.4319021943662107},
		 {-0.9689903846153848, 0.5673326167112793, 2.506, 1.122857365590812, -0.0966057692307692, 0.6669924088235596, 3.616, 0.6739521853046573, 0.003951923076923, 0.633044906351706, 3.331, 0.6330572416091977, 1.2995675655444168, 0.6533803067718419, 2.6027702160288726, 1.4545726804434036},
		 {-0.9996634615384616, 0.5627734482449898, 2.529, 1.1471882977020884, -0.1797692307692307, 0.6662315408147016, 3.76, 0.690059013641364, 0.0559423076923076, 0.6684299029315909, 3.927, 0.6707667828113412, 1.3426438450564038, 0.6629162955815313, 2.65577615344896, 1.497381217197339},
		 {-1.016298076923077, 0.5679237638405029, 2.471, 1.1642161237039743, -0.1188173076923076, 0.4991898005850441, 2.785, 0.5131354690677546, 0.0321634615384615, 0.7501480252715373, 3.927, 0.7508372314136553, 1.3256358978516638, 0.6520377341163843, 2.7256689996099355, 1.4773163981979671},
		 {-1.0167403846153844, 0.5427905814328025, 2.04, 1.1525548251601745, -0.1346346153846153, 0.3771533828383228, 2.088, 0.4004636735662222, -0.0451442307692307, 0.4815853111233698, 3.218, 0.4836966130350082, 1.172439504337495, 0.5900015262493314, 2.387001679844866, 1.312522834966193},
		 {-1.0511538461538463, 0.5265173634588594, 2.527, 1.1756466060460908, -0.1888557692307692, 0.422669706887733, 2.454, 0.4629429583569748, -0.1044423076923076, 0.358464187325142, 1.859, 0.3733694808507642, 1.1794464082313505, 0.5871729424462063, 2.748137627699384, 1.317522635187255},
		 {-1.0819807692307692, 0.4950565426286256, 2.58, 1.1898585484773454, -0.2024711538461538, 0.4341056889374975, 2.216, 0.4790013750582479, -0.0810288461538461, 0.2827219841500578, 1.325, 0.2941043934230993, 1.19874022314467, 0.5428857654591281, 2.8508609850887425, 1.3159418972443566},
		 {-1.0340673076923077, 0.4651576710441449, 1.984, 1.1338725041949078, -0.0587884615384615, 0.4756368336863447, 2.061, 0.4792561744716814, 0.0167692307692307, 0.2706301489390879, 1.516, 0.2711491925405359, 1.1562469039592618, 0.5019644591387602, 2.129745213710552, 1.2605059385634985},
		 {-1.0094423076923076, 0.4329181799344437, 1.9230000000000005, 1.0983587406111552, -0.076326923076923, 0.4976675489472344, 2.259, 0.5034866318598126, 0.029576923076923, 0.3674088241766114, 1.795, 0.3685973934546179, 1.1620039182285469, 0.4954812246912138, 2.129745213710552, 1.2632318670774578},
		 {-0.9962884615384616, 0.5198368211622708, 2.348, 1.123753095315323, -0.1013461538461538, 0.4958685226105568, 2.6870000000000003, 0.5061191901275673, 0.0041249999999999, 0.4573735572958515, 2.265, 0.4573921583701031, 1.1775750649769132, 0.5843819014388058, 2.5382039836725925, 1.3146045946917329},
		 {-1.0409903846153847, 0.5597149256402472, 2.348, 1.1819229157801088, -0.1207403846153845, 0.4448309747099346, 2.282, 0.4609260640693489, 0.026326923076923, 0.4517225033628264, 2.265, 0.4524890351412694, 1.202500505416718, 0.6067400405282564, 2.5382039836725925, 1.3469004945829115},
		 {-1.0072019230769231, 0.4445703928817921, 1.98, 1.1009534722579892, -0.1781442307692307, 0.349826122146341, 1.881, 0.3925731558478084, -0.0126057692307692, 0.4863396529624528, 3.1710000000000003, 0.4865029942986358, 1.1505463700506753, 0.5283374344053089, 2.60902919968592, 1.2660558416715944},
		 {-0.997846153846154, 0.411152081380684, 1.6, 1.079232588819125, -0.1244230769230769, 0.3658161500279912, 1.881, 0.3863968914112893, -0.0130865384615384, 0.4355323027536119, 3.1710000000000003, 0.4357288655009779, 1.1316853999678933, 0.4724334219673891, 2.60902919968592, 1.226338119236415},
		 {-1.0085288461538462, 0.4452766200898815, 1.812, 1.1024525848865687, -0.1104999999999999, 0.3348905963721011, 1.4500000000000002, 0.3526499135665023, 0.0514807692307692, 0.2985486682644644, 1.742, 0.3029547440181073, 1.1042802961934628, 0.4605543049668452, 2.1898656611720506, 1.1964719973257274},
		 {-0.9926538461538464, 0.4411919338396919, 1.812, 1.0862835637020525, -0.0900384615384615, 0.3899753424916494, 2.147, 0.4002345466194695, 0.0556826923076923, 0.3627555137794143, 1.947, 0.3670042574684931, 1.109802268919604, 0.4931842677720184, 2.1898656611720506, 1.2144512333053656},
		 {-1.0198173076923078, 0.5010786588877553, 2.168, 1.1362689661614185, -0.0669423076923077, 0.3994883705567149, 2.147, 0.4050583053947059, 0.0618653846153846, 0.400123491939395, 2.048, 0.4048779255718748, 1.147694553273975, 0.5494567692106491, 2.3124264386842905, 1.2724407761645151},
		 {-0.970875, 0.4980660615648212, 2.168, 1.091177376647671, -0.072, 0.4442259257145209, 2.24, 0.4500229694992502, 0.0662884615384615, 0.3358794046711535, 1.852, 0.3423581963607481, 1.105936592929561, 0.5360057158457867, 2.3124264386842905, 1.2289824551229362},
		 {-0.9507019230769232, 0.3816070491962927, 1.6749999999999998, 1.0244306157756422, -0.1264423076923077, 0.5174594526464235, 2.24, 0.5326837169537777, 0.0505961538461538, 0.3933053110212406, 2.453, 0.3965463887889265, 1.1518769492412668, 0.4045226336242806, 1.7815639579576947, 1.2208435883878377},
		 {-0.966201923076923, 0.3946566272822999, 1.608, 1.0436953624575442, -0.1672980769230769, 0.4961502346879594, 2.195, 0.5235968887637482, 0.065826923076923, 0.4048386060734025, 2.453, 0.4101554348892999, 1.1624975951033976, 0.424594552115909, 1.7311169744305572, 1.237611082815475},
		 {-1.0347307692307692, 0.5064190312449766, 2.766, 1.152010416619572, -0.1051153846153846, 0.4462228510959929, 2.195, 0.4584365571407639, -0.0587788461538461, 0.4748133025146015, 3.0040000000000004, 0.4784376918680216, 1.2048382957141088, 0.5608559379232773, 3.397945724991955, 1.3289825814972434},
		 {-0.9629711538461538, 0.0050885556564352, 0.029, 0.9629845982872528, -0.1309038461538461, 0.0103566396677252, 0.0439999999999999, 0.1313128970173034, -0.1735288461538461, 0.0183962562719289, 0.086, 0.1745012398016349, 0.9874279476570887, 0.0043754245000578, 0.0273572704032115, 0.9874376416533076},
		 {-0.9510480769230768, 0.0204056835067756, 0.0789999999999999, 0.9512669638637, -0.1549134615384615, 0.0545231268110012, 0.28, 0.164228352981685, -0.1656826923076923, 0.0372747760719366, 0.208, 0.1698239189912259, 0.9800667834001852, 0.0137496181289161, 0.0561880830937051, 0.9801632271836548},
		 {-1.004875, 0.1183807975186594, 0.522, 1.0118239860994371, -0.1886826923076923, 0.1456939801580351, 0.716, 0.2383860193693607, -0.1429615384615384, 0.1703783077491946, 0.873, 0.2224112614747042, 1.055588323046622, 0.125760624025616, 0.5533032183990552, 1.0630533581658506},
		 {-1.0031826923076923, 0.2660498711354941, 1.377, 1.0378622490855534, -0.1714807692307692, 0.4320802761233066, 3.272, 0.4648645170700483, -0.0734038461538461, 0.3941654894357574, 2.073, 0.4009420877038325, 1.135351741920542, 0.4061872069846499, 2.572756498241842, 1.2058240439632972},
		 {-0.985471153846154, 0.2602923266670486, 1.377, 1.019267133966663, -0.201451923076923, 0.4370579058582797, 3.272, 0.4812509640349985, -0.0144423076923076, 0.3771332101659295, 2.073, 0.3774096427776302, 1.1153699012687377, 0.4109695883815928, 2.572756498241842, 1.1886740592907583},
		 {-0.9935480769230768, 0.205816987403844, 0.978, 1.0146420124662383, -0.2063076923076923, 0.3083999674786435, 1.753, 0.3710436683817066, -0.0294903846153846, 0.3545645486202951, 2.193, 0.3557888445736837, 1.0920935616597636, 0.3179452339823033, 1.6819482251075717, 1.1374346219588929},
		 {-0.9447884615384614, 0.1860011203996923, 0.978, 0.9629234932465578, -0.1562211538461538, 0.3028581781807722, 1.945, 0.3407757693850899, -0.0849038461538461, 0.3372966486877335, 2.193, 0.3478184760873009, 1.0345754913896563, 0.3065632459537464, 1.6819482251075717, 1.079040069299489},
		 {-0.9742596153846156, 0.1432543458323414, 0.6719999999999999, 0.9847352973105165, -0.1728173076923077, 0.2141729066226935, 1.041, 0.2752014821348729, -0.1145576923076923, 0.1982993961608342, 1.05, 0.229011168689685, 1.0343986953889108, 0.1670476456008762, 0.6830807368388763, 1.047800351652488},
		 {-1.0036346153846154, 0.2192785398358543, 1.136, 1.0273098457771974, -0.2215, 0.4507036165818953, 2.6, 0.5021911986484828, -0.0591826923076923, 0.3718995099078171, 1.957, 0.3765791238749986, 1.1413440261182417, 0.3830237196485783, 2.0477815564298165, 1.2038992299064033},
		 {-1.0332403846153846, 0.209016032472682, 1.136, 1.054169528221514, -0.2264423076923076, 0.4411774199824452, 2.6, 0.4958967983516174, -0.032201923076923, 0.360905948216208, 1.907, 0.362339712573287, 1.1625522199248008, 0.370066794108528, 2.0477815564298165, 1.2200315963752113},
		 {-0.9954615384615384, 0.2653733916244214, 1.444, 1.0302265340877517, -0.1677211538461538, 0.4031435957364125, 2.909, 0.4366407496223517, -0.0364711538461538, 0.4146724832909325, 2.677, 0.4162732437492691, 1.1107156855560452, 0.4377395745081015, 2.698680286872856, 1.1938614949946116},
		 {-0.951778846153846, 0.2392516359855153, 1.444, 0.9813889735001572, -0.2181057692307692, 0.4034240448544384, 2.909, 0.4586077698191141, -0.0302307692307692, 0.3909264693492496, 2.677, 0.3920936161762313, 1.0700732023223931, 0.4267624038780898, 2.698680286872856, 1.1520342042197826},
		 {-0.98975, 0.1949585631516447, 0.8390000000000001, 1.008768508551964, -0.2482307692307692, 0.2706118150374625, 1.77, 0.3672182855343252, -0.031201923076923, 0.3150788783966427, 1.845, 0.3166200556114293, 1.0792979846631936, 0.2963566989191846, 1.6612806968411018, 1.1192459214543995},
		 {-0.974701923076923, 0.2037068916080393, 0.8390000000000001, 0.99576118449077, -0.1381057692307692, 0.344575516962237, 2.479, 0.371221618961794, -0.039451923076923, 0.3684972570560603, 1.853, 0.3706031336784778, 1.079690725882544, 0.3177427356504156, 1.6612806968411018, 1.1254743487149694},
		 {-0.9789326923076924, 0.1222163328206835, 0.494, 0.9865323350387069, -0.1551346153846154, 0.2881100570192254, 1.614, 0.3272218725057264, -0.0890673076923077, 0.2695405729564188, 1.7009999999999998, 0.2838751587744704, 1.063099140096787, 0.1752869818833659, 1.0750091038168024, 1.077453158003775},
		 {-0.9960096153846154, 0.1636418753531101, 0.752, 1.0093630750664957, -0.2134615384615384, 0.2589841442680392, 1.221, 0.3356167686284691, -0.0563461538461538, 0.2896780961831323, 1.628, 0.2951072490833433, 1.0817437832300447, 0.2199343279185769, 1.065384084708532, 1.1038753195691289},
		 {-1.008846153846154, 0.1654772683221503, 0.752, 1.0223273881010615, -0.2026153846153846, 0.2410927170713625, 1.221, 0.3149264871484967, -0.019951923076923, 0.2699184128800523, 1.628, 0.2706548149325148, 1.0815425043103282, 0.2187505908232669, 1.065384084708532, 1.1034427985244113},
		 {-0.995528846153846, 0.1728550947565157, 0.677, 1.010423954242818, -0.1977596153846154, 0.2502722554152204, 1.309, 0.3189750261504688, -0.0564326923076923, 0.2765835095904433, 1.395, 0.282281927403193, 1.070364026178228, 0.2381293191049336, 1.207664421665578, 1.0965330460838132},
		 {-0.9518076923076924, 0.1461610726958366, 0.677, 0.962964663062821, -0.1514903846153846, 0.2524158273713128, 1.315, 0.2943859482693791, -0.0976730769230769, 0.2612317510117911, 1.395, 0.2788943486202395, 1.02127234397736, 0.2207914988523115, 1.207664421665578, 1.0448665400607209},
		 {-0.9706826923076924, 0.1459388876592288, 0.652, 0.9815920986218885, -0.1690192307692308, 0.1967085886811929, 0.798, 0.2593487405613708, -0.1015384615384615, 0.1991064618140121, 0.992, 0.2235026673390998, 1.0258226261206995, 0.1686007098271408, 0.6849637722737676, 1.039585619184579},
		 {-0.9946634615384616, 0.1917764930337538, 0.78, 1.0129825393361922, -0.2306442307692308, 0.2999542246573515, 1.899, 0.3783771902175434, -0.027201923076923, 0.3533102901843477, 2.16, 0.3543559026871583, 1.1039873571647687, 0.2758313688950247, 1.4647941305643863, 1.1379239995914288},
		 {-1.0107403846153846, 0.1568612809013298, 0.78, 1.0228399613519514, -0.2228942307692307, 0.299587052915189, 1.899, 0.3734089452391511, -0.0226442307692307, 0.3338329821433406, 2.16, 0.3346000913834994, 1.111779601706359, 0.2480708876643385, 1.4647941305643863, 1.139119417829809},
		 {-0.9946634615384616, 0.1546087251603545, 0.6819999999999999, 1.0066077983084498, -0.1914711538461538, 0.3229273244248729, 1.684, 0.3754241063322713, -0.056326923076923, 0.2895992072047323, 1.555, 0.2950261396502402, 1.0818963358585103, 0.2659760529890266, 1.4763764910313433, 1.1141108303520313},
		 {-0.9536538461538462, 0.1400264926328344, 0.6819999999999999, 0.9638791817043652, -0.1661153846153845, 0.3003027097040939, 1.715, 0.3431851372969675, -0.0756538461538461, 0.2865040196130551, 1.6, 0.2963242441858372, 1.032747384776833, 0.2609214677130558, 1.4763764910313433, 1.0651981848824768},
		 {-0.9590480769230768, 0.1516937945467582, 0.6099999999999999, 0.970970762254892, -0.1657307692307692, 0.2060905901804998, 0.938, 0.2644617538147421, -0.0924230769230769, 0.2235896263378897, 1.07, 0.2419387239650696, 1.0184529230486714, 0.1844240496032948, 0.729716003995784, 1.0350162252537212},
		 {-0.9865096153846152, 0.1927410576191792, 0.812, 1.005161845942464, -0.1866538461538461, 0.2997103656105972, 1.578, 0.3530806728475258, -0.0144423076923076, 0.3554498457243213, 1.864, 0.3557431279405452, 1.088203851639069, 0.2781759307196451, 1.3305353470888333, 1.1231960964826428},
		 {-1.0320384615384617, 0.1713513553557383, 0.7370000000000001, 1.0461666564543737, -0.1900769230769231, 0.2961637960366531, 1.578, 0.3519122486774661, -0.0167596153846153, 0.3699998309561024, 1.967, 0.3703792105604533, 1.1358557817713808, 0.2555764200353076, 1.2769944211031456, 1.1642541232314956},
		 {-0.998903846153846, 0.2343150213195396, 1.258, 1.0260177498839496, -0.1279807692307692, 0.3122863879385651, 1.434, 0.3374935042109928, -0.0126346153846153, 0.3123780702958758, 1.766, 0.3126334791855989, 1.0909699065508214, 0.2722841232421068, 1.2656680526415425, 1.12443496066657},
		 {-0.9441538461538462, 0.2088204404060123, 1.258, 0.9669707656069348, -0.1636826923076923, 0.2727603648324307, 1.434, 0.3181041344978329, -0.0503749999999999, 0.2603083300293947, 1.398, 0.2651378270026597, 1.0240857640334644, 0.2403520691293598, 1.2656680526415425, 1.0519129095275754},
		 {-0.9760961538461538, 0.1890516575330042, 0.8659999999999999, 0.994235500658285, -0.1947211538461538, 0.1903064056043654, 1.082, 0.2722734944301974, -0.017875, 0.298970177555066, 1.354, 0.2995040612284042, 1.04647341335826, 0.2392345384033868, 1.033629327911345, 1.073470898175991},
		 {-0.9835865384615384, 0.2049380117619492, 0.8659999999999999, 1.0047099418776009, -0.1507980769230769, 0.2287267171760831, 1.276, 0.2739634485726995, 0.0248557692307692, 0.294164279660625, 1.342, 0.2952125212322602, 1.0528390490259252, 0.2513531539488448, 1.033629327911345, 1.082427120481488},
		 {-1.014576923076923, 0.1459436595921451, 0.703, 1.0250199435208005, -0.198125, 0.2015761302785548, 1.076, 0.2826419146607186, -0.0710673076923077, 0.2533726832622662, 1.327, 0.2631506770771336, 1.0823286721760583, 0.1684198942234142, 0.6486758844160021, 1.0953541050202056},
		 {-0.991923076923077, 0.2190574517330175, 1.012, 1.0158235859106186, -0.1775096153846154, 0.2779970598624376, 1.619, 0.3298363667732135, -0.0200961538461538, 0.3693301764220957, 1.946, 0.3698765126571091, 1.091608578935745, 0.293068134650851, 1.4533857165109, 1.1302646686302489},
		 {-0.9464903846153846, 0.1931726009394143, 1.012, 0.9660019161073528, -0.1917980769230769, 0.2674321761539842, 1.619, 0.3290994851923141, -0.0315192307692307, 0.3050609958166383, 1.873, 0.3066849736731865, 1.0309955977140657, 0.2693880540188494, 1.4533857165109, 1.0656086740233706},
		 {-0.9811153846153846, 0.1826993804298949, 0.8729999999999999, 0.9979811929783354, -0.214375, 0.2809938470274887, 1.652, 0.353432005755432, -0.0286730769230769, 0.3207338173358716, 1.717, 0.3220129297451842, 1.0661064055089202, 0.2966312581079345, 1.6750150599048534, 1.1066042522753317},
		 {-0.9820192307692308, 0.2030358523081212, 0.8749999999999999, 1.002788774829015, -0.1469423076923077, 0.3397209212926182, 2.339, 0.3701382797737166, -0.0346826923076923, 0.3590145236087006, 1.767, 0.3606858984042657, 1.0834933942579823, 0.3142038430444977, 1.6750150599048534, 1.1281320802036503},
		 {-1.012, 0.1295404599699675, 0.8049999999999999, 1.0202571885408265, -0.1595673076923077, 0.259247459909783, 1.863, 0.3044190716000661, -0.099576923076923, 0.2384857555941271, 1.293, 0.2584395852627248, 1.084605834143554, 0.1549738871410648, 0.7878130403552599, 1.0956216140410184},
		 {-0.9955384615384616, 0.1747142129679716, 0.864, 1.0107531274328982, -0.1589326923076923, 0.3531643566066186, 2.275, 0.387278534728609, -0.0445673076923077, 0.3360656061299947, 1.786, 0.3390078709093072, 1.0988620249509151, 0.2811318813940502, 1.596396674341709, 1.1342543297759038},
		 {-0.962076923076923, 0.1605258002452524, 0.864, 0.975377126275544, -0.1683557692307692, 0.338227589463675, 2.275, 0.377811549992443, -0.0560673076923076, 0.2975251206079101, 1.786, 0.302761854242927, 1.0527434867333236, 0.2783846211528406, 1.596396674341709, 1.0889292199926708},
		 {-0.9847980769230767, 0.1477686848661481, 0.618, 0.9958226933236968, -0.1350192307692307, 0.2140583574621843, 1.377, 0.2530833322779733, -0.0637307692307692, 0.2613376548117113, 1.429, 0.2689962467567731, 1.0426756288074608, 0.2022387783675069, 0.962103683591412, 1.062107805443786},
		 {-0.9581153846153844, 0.1217888547771469, 0.507, 0.9658248368025204, -0.0235096153846153, 0.0800446984734043, 0.395, 0.0834257500369686, 0.1874615384615384, 0.1118707979938776, 0.472, 0.2183046125169, 0.9871382920466192, 0.1139840663219367, 0.5252523997071242, 0.9936973256480064},
		 {-0.9242403846153848, 0.2036359636134422, 1.257, 0.9464078899875936, 0.0040192307692307, 0.1856101156047075, 1.033, 0.1856536270337028, 0.2755865384615384, 0.2153139304943849, 0.921, 0.3497256479673086, 1.0041542830383652, 0.2100889529780162, 1.3008237266230926, 1.0258962873057356},
		 {-0.9747596153846154, 0.2184622170814893, 1.257, 0.9989404627288472, -0.1103076923076923, 0.2485646130564552, 1.073, 0.2719414529749994, 0.158625, 0.2876652096388064, 1.185, 0.3285013903494754, 1.060170112338867, 0.2361920792236897, 1.3008237266230926, 1.0861617583880476},
		 {-1.0066923076923078, 0.3082622533880937, 1.342, 1.0528319045463854, -0.1369326923076923, 0.2324548038959185, 1.023, 0.2697884320665418, 0.0215, 0.3178323517928184, 1.641, 0.318558713342068, 1.0770693711421422, 0.3502028567863439, 1.4709672458394545, 1.1325725014999466},
		 {-0.9956346153846152, 0.3206857453385067, 1.342, 1.0460055614648445, -0.1682115384615384, 0.242380766606408, 1.105, 0.2950314520391134, 0.0121153846153846, 0.3226160288500959, 1.603, 0.3228434366924386, 1.0766673517826535, 0.3552273786300881, 1.4709672458394545, 1.1337544164955111},
		 {-0.9935673076923076, 0.3266944810234984, 1.343, 1.045899268020661, -0.1526346153846153, 0.2084868127951201, 0.9, 0.258387455041991, 0.0126057692307692, 0.3302253722916782, 1.841, 0.3304658861714427, 1.0684697621777144, 0.358119288791048, 1.4544308124141343, 1.1268882188097928},
		 {-0.9927596153846152, 0.3379571973123766, 1.343, 1.0487071665407108, -0.1323653846153846, 0.2226670961881258, 0.852, 0.259039052594837, 0.0122115384615384, 0.3257712054930613, 1.841, 0.3259999999999999, 1.066087505724954, 0.3696232975073715, 1.4544308124141343, 1.1283456704056063},
		 {-1.000326923076923, 0.3804447660888223, 1.545, 1.0702299627075125, -0.1219423076923076, 0.2531031952402585, 1.103, 0.2809468879453087, 0.0147884615384615, 0.3531090394099502, 2.041, 0.3534185794602376, 1.079398584370711, 0.4290998896402496, 1.8623955817578208, 1.1615627487272346},
		 {-1.005894230769231, 0.3789840142323143, 1.545, 1.0749195721254972, -0.1225865384615384, 0.2348603763031314, 1.042, 0.2649280199775606, 0.001, 0.3661092995688162, 2.041, 0.3661106652786411, 1.0844013439881135, 0.4286603395408004, 1.8623955817578208, 1.16605144034835},
		 {-0.9877115384615386, 0.3634335108241132, 1.487, 1.0524533243807064, -0.1258269230769231, 0.220239617860066, 0.971, 0.2536491747397453, -0.001701923076923, 0.3632910964578302, 2.122, 0.3632950829665773, 1.0667926720273753, 0.4073482736707488, 1.8794991452337133, 1.1419190957129346},
		 {-0.9976634615384616, 0.3593268442137786, 1.487, 1.0604000016321853, -0.1139807692307692, 0.219075021430543, 0.982, 0.2469523856317868, -0.025701923076923, 0.385171986555449, 2.236, 0.3860285586286629, 1.0816135575959234, 0.4056646451594994, 1.8794991452337133, 1.1551847005166282},
		 {-0.9719423076923076, 0.2940020874769912, 1.2160000000000002, 1.0154354124822893, -0.1332692307692307, 0.2088312361863057, 0.981, 0.2477320590414633, -0.0026826923076923, 0.3265859017760952, 1.637, 0.3265969198827862, 1.0453645496607171, 0.3261269022781919, 1.251280495809814, 1.095055157550031},
		 {-0.9894423076923076, 0.2811125502398761, 1.1760000000000002, 1.028601159903024, -0.1408942307692307, 0.2110322577542822, 0.946, 0.2537435675577276, 0.0068942307692307, 0.3051992072738101, 1.505, 0.3052770652021889, 1.0562143631493426, 0.3162458692951733, 1.2432497479078617, 1.1025426208402245},
		 {-0.9972307692307693, 0.2517292207744583, 1.017, 1.0285119385268735, -0.1452596153846153, 0.2221595924621059, 1.036, 0.2654340603325341, -0.0054134615384615, 0.2635733590255619, 1.334, 0.2636289459711246, 1.0562259286831526, 0.286668897524969, 1.0738369811110646, 1.0944369644848302},
		 {-0.9788653846153844, 0.2409642910702868, 1.017, 1.0080879082546477, -0.1541730769230769, 0.2424209404157797, 1.036, 0.287292968935893, 0.0099038461538461, 0.2290149272608316, 0.992, 0.2292289752123912, 1.0373043481381758, 0.2744523513832377, 1.0738369811110646, 1.0729978582672726},
		 {-1.0015576923076923, 0.2468233885456078, 1.014, 1.031522949891977, -0.1501057692307692, 0.2305615184996616, 0.963, 0.2751188030092286, -0.001326923076923, 0.2989574333704643, 1.651, 0.2989603781311291, 1.0711537255239891, 0.2858967574343281, 1.105993668661437, 1.1086510991359655},
		 {-0.9792211538461538, 0.2552181931034234, 1.014, 1.0119339870914354, -0.1176346153846153, 0.1923793356932473, 0.692, 0.2254943714119302, 0.0066057692307692, 0.2965721931266428, 1.651, 0.2966457515675506, 1.0393013922182948, 0.2875924613501234, 1.105993668661437, 1.0783583855529235},
		 {-0.9688942307692308, 0.1686950433742013, 0.83, 0.9834704103718236, -0.1928173076923077, 0.169843919550086, 0.765, 0.2569542199572642, -0.0025384615384615, 0.2685740809948878, 1.367, 0.2685860770204419, 1.030911553768885, 0.2063961441156862, 0.8945482710280693, 1.0513695829726102},
		 {-0.9671730769230767, 0.1624931029487626, 0.7270000000000001, 0.9807281831530944, -0.1521730769230769, 0.2172989097952975, 0.915, 0.2652837377949533, -0.0481057692307692, 0.262686707163804, 1.367, 0.2670551837239752, 1.0315456762986317, 0.1985830295686818, 0.7813055623716944, 1.0504864120601831},
		 {-0.9959807692307692, 0.2435971209240479, 1.011, 1.025337627320874, -0.14175, 0.2425406686754583, 0.911, 0.280925325418586, -0.0115576923076923, 0.285284669804467, 1.516, 0.2855186912916965, 1.065284279412345, 0.2773564774354162, 1.08814480736173, 1.1007984427398425},
		 {-0.9865192307692308, 0.3107867491968268, 1.374, 1.034315520599902, -0.1370192307692307, 0.2370451507125412, 0.883, 0.2737967733135711, -0.0036153846153846, 0.2796189133202376, 1.516, 0.279642285236528, 1.052880155885486, 0.3382550136592678, 1.4694539458259968, 1.1058811314617305},
		 {-0.9795576923076924, 0.3181065020894694, 1.374, 1.0299150543762186, -0.1253461538461538, 0.2467716855575197, 0.94, 0.2767813633121332, -0.0264326923076923, 0.273708497536194, 1.495, 0.274981870031742, 1.0440197493902454, 0.3506718323974358, 1.4694539458259968, 1.1013391717149836},
		 {-0.9973461538461538, 0.3279196597559193, 1.358, 1.0498717320921418, -0.1282596153846153, 0.2618013043979488, 0.997, 0.2915312194655607, -0.0061153846153846, 0.322218282072534, 1.5510000000000002, 0.3222763088264001, 1.0781554556998671, 0.3586975583198357, 1.4160781944008476, 1.1362583883078707},
		 {-0.986846153846154, 0.3163410029975798, 1.358, 1.0363092982012954, -0.1060576923076923, 0.2537036743208606, 0.877, 0.2749796146290456, -0.0219134615384615, 0.282257285474445, 1.428, 0.2831066495156905, 1.0578612605354945, 0.3326104004060224, 1.4160781944008476, 1.1089184483089818},
		 {-0.9929038461538462, 0.290393549913494, 1.25, 1.0344981689391537, -0.1148461538461538, 0.2190873451226688, 0.839, 0.2473639097486815, 0.0067788461538461, 0.3172407165620808, 1.502, 0.3173131339859729, 1.0671405758496015, 0.3054078940695479, 1.1928255660345095, 1.109983328876887},
		 {-1.0034807692307692, 0.2893686755670148, 1.25, 1.0443696111125529, -0.1235384615384615, 0.2239298878545609, 0.921, 0.2557466444625347, 0.0024807692307692, 0.33245586696031, 1.541, 0.3324651225201039, 1.0815637074054978, 0.3112350161611205, 1.1509026324696618, 1.1254542587158034},
		 {-0.9773365384615385, 0.3006113517796475, 1.234, 1.0225232976469385, -0.1064615384615384, 0.2245770778715527, 0.921, 0.2485335451743347, 0.0044807692307692, 0.3314276223565965, 1.735, 0.3314579100788608, 1.0529446965779916, 0.3293852294955252, 1.251814363890449, 1.103262055661092},
		 {-0.9624519230769232, 0.3342511400304962, 1.234, 1.0188412677380878, -0.1228173076923076, 0.2251350348817638, 0.827, 0.2564563803066712, -0.0062403846153846, 0.3583502931488295, 1.898, 0.3584046246911443, 1.0470071553907725, 0.3688323405108029, 1.326511604055126, 1.1100726457516883},
		 {-0.9930384615384616, 0.3365305427639781, 1.397, 1.0485123710799469, -0.1305096153846153, 0.2683806494225458, 1.262, 0.2984307837544707, -0.0182884615384615, 0.3662208684417758, 1.99, 0.3666772317825206, 1.0829464626689431, 0.3874509985798403, 1.6296219618016607, 1.150170125376108},
		 {-0.9986538461538464, 0.3021395745102039, 1.397, 1.043358915677188, -0.1294038461538461, 0.2622659219787446, 1.215, 0.2924530205533347, -0.0052980769230769, 0.3489542861786564, 1.876, 0.3489945034832761, 1.082866676336372, 0.3511744878199489, 1.619849001636835, 1.1383864719924357},
		 {-0.9937980769230768, 0.283075023346207, 1.205, 1.0333276762665662, -0.1322692307692307, 0.24202424508115, 1.063, 0.2758095078408005, -0.0032403846153846, 0.338640622284732, 1.81, 0.3386561252271191, 1.072754740986262, 0.3282106153054621, 1.4938128839046128, 1.121839980704776},
		 {-0.9998269230769232, 0.2730585821305529, 1.205, 1.0364433729753957, -0.12175, 0.2315497018419089, 1.013, 0.2616071996774495, -0.0094903846153846, 0.318625292201704, 1.729, 0.3187665983611978, 1.070940887190723, 0.3120111419190172, 1.4938128839046128, 1.1154664210716796},
		 {-0.9972980769230768, 0.2452207357200263, 0.907, 1.0270037309871558, -0.0989615384615384, 0.2006004890647521, 0.995, 0.2236826821810135, -0.0205865384615384, 0.2797409382108644, 1.368, 0.2804974118898837, 1.0544050074183788, 0.2677302451670386, 0.9885785571739634, 1.087864607313867},
		 {-1.0187596153846152, 0.20278595646226, 0.858, 1.0387460219307332, -0.0711346153846153, 0.2448265499716195, 0.993, 0.2549513151111856, -0.0454903846153846, 0.2386536352118946, 1.114, 0.24295047374374, 1.074899736301276, 0.2181947770813983, 0.9049739523756272, 1.0968219563111208},
		 {-0.986721153846154, 0.2470576644277906, 1.425, 1.017180478086362, -0.0802211538461538, 0.24624331137854, 1.004, 0.2589810841028296, -0.051, 0.2475034187798065, 1.13, 0.2527032692857223, 1.0499555949750177, 0.2513553616126498, 1.4145774331861918, 1.0796232070638203},
		 {-0.9865576923076924, 0.2185207623880956, 1.425, 1.0104689029584997, -0.1800865384615384, 0.1777378747664078, 0.966, 0.2530255193879432, -0.0355480769230769, 0.2431668815936785, 1.13, 0.2457514965914207, 1.0490660397077702, 0.2119517863016741, 1.3988192650647706, 1.07026310568225},
		 {-0.9568365384615384, 0.2620378389652078, 1.342, 0.9920685411727436, -0.165375, 0.1792070776579215, 0.784, 0.2438525523911782, 0.0299903846153846, 0.2625034979690859, 1.255, 0.2642111080469264, 1.02117170894117, 0.2658569317619207, 1.3035130414214513, 1.0552116220491945},
		 {-0.9781538461538462, 0.3005666369616526, 1.427, 1.0232913807904376, -0.1675865384615384, 0.2089257602123908, 0.949, 0.2678343166098141, 0.0387596153846153, 0.2780914865786876, 1.33, 0.2807795980699233, 1.0474466275407652, 0.3171012713623695, 1.4400886110123876, 1.094393738033142},
		 {-1.010701923076923, 0.3123035961210628, 1.58, 1.0578525008060142, -0.1297884615384615, 0.2295869900946263, 0.959, 0.2637332568509909, -0.0026538461538461, 0.3099678571807198, 1.513, 0.3099792176656612, 1.083158248270143, 0.3338599539024408, 1.4570014562078373, 1.1334435405503818},
		 {-0.9864326923076924, 0.3191104452049562, 1.58, 1.036764646721862, -0.1247884615384615, 0.2427659791570776, 0.985, 0.2729605846440668, -0.0121249999999999, 0.2979221854877029, 1.481, 0.2981688183408339, 1.0608630101497842, 0.3359504894895181, 1.4273694517100344, 1.1127861688987275}};

int sizeOfTestData = sizeof(testData) / sizeof(testData[0]);

uint32_t timestamp;

/* USER CODE END PD */

ADC_HandleTypeDef hadc3;

TIM_HandleTypeDef htim16;

void SystemClock_Config(void);
static void MX_GPIO_Init(void);
static void MX_ADC3_Init(void);
static void MX_TIM16_Init(void);
/* USER CODE BEGIN PFP */

void FillBuffer(float* buffer, uint32_t size);
void Inference(void);

/* USER CODE END PFP */

int main(void)
{

  /* MCU Configuration--------------------------------------------------------*/

  /* Reset of all peripherals, Initializes the Flash interface and the Systick. */
  HAL_Init();

  /* Configure the system clock */
  SystemClock_Config();

  /* Initialize all configured peripherals */
  MX_GPIO_Init();
  MX_ADC3_Init();
  MX_TIM16_Init();
  MX_USB_DEVICE_Init();

  /* Infinite loop */
  /* USER CODE BEGIN WHILE */

  HAL_TIM_Base_Start(&htim16);

        enum neai_state error_code = neai_classification_init(knowledge);
          if(error_code != NEAI_OK) {
        	  snprintf(SendBuffer,BUFSIZE,"Napaka pri inicializaciji znanja. \r\n");
        	  CDC_Transmit_FS(SendBuffer,strlen(SendBuffer));

        	  Error_Handler();
          }
          else {
        	  snprintf(SendBuffer,BUFSIZE,"Opravljena inicializacija znanja. \r\n");
        	  CDC_Transmit_FS(SendBuffer,strlen(SendBuffer));
          }

  while (1)
  {
	  Inference();
    /* USER CODE END WHILE */

  }
}

void SystemClock_Config(void)
{
  RCC_OscInitTypeDef RCC_OscInitStruct = {0};
  RCC_ClkInitTypeDef RCC_ClkInitStruct = {0};

  /** Supply configuration update enable
  */
  HAL_PWREx_ConfigSupply(PWR_LDO_SUPPLY);

  /** Configure the main internal regulator output voltage
  */
  __HAL_PWR_VOLTAGESCALING_CONFIG(PWR_REGULATOR_VOLTAGE_SCALE3);

  while(!__HAL_PWR_GET_FLAG(PWR_FLAG_VOSRDY)) {}

  /** Initializes the RCC Oscillators according to the specified parameters
  * in the RCC_OscInitTypeDef structure.
  */
  RCC_OscInitStruct.OscillatorType = RCC_OSCILLATORTYPE_HSI|RCC_OSCILLATORTYPE_HSE;
  RCC_OscInitStruct.HSEState = RCC_HSE_BYPASS;
  RCC_OscInitStruct.HSIState = RCC_HSI_DIV1;
  RCC_OscInitStruct.HSICalibrationValue = RCC_HSICALIBRATION_DEFAULT;
  RCC_OscInitStruct.PLL.PLLState = RCC_PLL_ON;
  RCC_OscInitStruct.PLL.PLLSource = RCC_PLLSOURCE_HSE;
  RCC_OscInitStruct.PLL.PLLM = 22;
  RCC_OscInitStruct.PLL.PLLN = 169;
  RCC_OscInitStruct.PLL.PLLP = 2;
  RCC_OscInitStruct.PLL.PLLQ = 4;
  RCC_OscInitStruct.PLL.PLLR = 2;
  RCC_OscInitStruct.PLL.PLLRGE = RCC_PLL1VCIRANGE_0;
  RCC_OscInitStruct.PLL.PLLVCOSEL = RCC_PLL1VCOWIDE;
  RCC_OscInitStruct.PLL.PLLFRACN = 0;
  if (HAL_RCC_OscConfig(&RCC_OscInitStruct) != HAL_OK)
  {
    Error_Handler();
  }

  /** Initializes the CPU, AHB and APB buses clocks
  */
  RCC_ClkInitStruct.ClockType = RCC_CLOCKTYPE_HCLK|RCC_CLOCKTYPE_SYSCLK
                              |RCC_CLOCKTYPE_PCLK1|RCC_CLOCKTYPE_PCLK2
                              |RCC_CLOCKTYPE_D3PCLK1|RCC_CLOCKTYPE_D1PCLK1;
  RCC_ClkInitStruct.SYSCLKSource = RCC_SYSCLKSOURCE_HSI;
  RCC_ClkInitStruct.SYSCLKDivider = RCC_SYSCLK_DIV1;
  RCC_ClkInitStruct.AHBCLKDivider = RCC_HCLK_DIV1;
  RCC_ClkInitStruct.APB3CLKDivider = RCC_APB3_DIV1;
  RCC_ClkInitStruct.APB1CLKDivider = RCC_APB1_DIV1;
  RCC_ClkInitStruct.APB2CLKDivider = RCC_APB2_DIV1;
  RCC_ClkInitStruct.APB4CLKDivider = RCC_APB4_DIV1;

  if (HAL_RCC_ClockConfig(&RCC_ClkInitStruct, FLASH_LATENCY_1) != HAL_OK)
  {
    Error_Handler();
  }
}

static void MX_ADC3_Init(void)
{

  ADC_ChannelConfTypeDef sConfig = {0};

  /** Common config
  */
  hadc3.Instance = ADC3;
  hadc3.Init.Resolution = ADC_RESOLUTION_16B;
  hadc3.Init.ScanConvMode = ADC_SCAN_DISABLE;
  hadc3.Init.EOCSelection = ADC_EOC_SINGLE_CONV;
  hadc3.Init.LowPowerAutoWait = DISABLE;
  hadc3.Init.ContinuousConvMode = DISABLE;
  hadc3.Init.NbrOfConversion = 1;
  hadc3.Init.DiscontinuousConvMode = DISABLE;
  hadc3.Init.ExternalTrigConv = ADC_SOFTWARE_START;
  hadc3.Init.ExternalTrigConvEdge = ADC_EXTERNALTRIGCONVEDGE_NONE;
  hadc3.Init.ConversionDataManagement = ADC_CONVERSIONDATA_DR;
  hadc3.Init.Overrun = ADC_OVR_DATA_PRESERVED;
  hadc3.Init.LeftBitShift = ADC_LEFTBITSHIFT_NONE;
  hadc3.Init.OversamplingMode = DISABLE;
  if (HAL_ADC_Init(&hadc3) != HAL_OK)
  {
    Error_Handler();
  }

  /** Configure Regular Channel
  */
  sConfig.Channel = ADC_CHANNEL_1;
  sConfig.Rank = ADC_REGULAR_RANK_1;
  sConfig.SamplingTime = ADC_SAMPLETIME_1CYCLE_5;
  sConfig.SingleDiff = ADC_DIFFERENTIAL_ENDED;
  sConfig.OffsetNumber = ADC_OFFSET_NONE;
  sConfig.Offset = 0;
  sConfig.OffsetSignedSaturation = DISABLE;
  if (HAL_ADC_ConfigChannel(&hadc3, &sConfig) != HAL_OK)
  {
    Error_Handler();
  }

}

static void MX_TIM16_Init(void)
{

  htim16.Instance = TIM16;
  htim16.Init.Prescaler = 64000 - 1;
  htim16.Init.CounterMode = TIM_COUNTERMODE_UP;
  htim16.Init.Period = 65535;
  htim16.Init.ClockDivision = TIM_CLOCKDIVISION_DIV1;
  htim16.Init.RepetitionCounter = 0;
  htim16.Init.AutoReloadPreload = TIM_AUTORELOAD_PRELOAD_DISABLE;
  if (HAL_TIM_Base_Init(&htim16) != HAL_OK)
  {
    Error_Handler();
  }

}

static void MX_GPIO_Init(void)
{
  GPIO_InitTypeDef GPIO_InitStruct = {0};

  /* GPIO Ports Clock Enable */
  __HAL_RCC_GPIOI_CLK_ENABLE();
  __HAL_RCC_GPIOB_CLK_ENABLE();
  __HAL_RCC_GPIOK_CLK_ENABLE();
  __HAL_RCC_GPIOG_CLK_ENABLE();
  __HAL_RCC_GPIOC_CLK_ENABLE();
  __HAL_RCC_GPIOE_CLK_ENABLE();
  __HAL_RCC_GPIOJ_CLK_ENABLE();
  __HAL_RCC_GPIOD_CLK_ENABLE();
  __HAL_RCC_GPIOH_CLK_ENABLE();
  __HAL_RCC_GPIOA_CLK_ENABLE();
  __HAL_RCC_GPIOF_CLK_ENABLE();

  /*Configure GPIO pin Output Level */
  HAL_GPIO_WritePin(LD2_GPIO_Port, LD2_Pin, GPIO_PIN_RESET);

  /*Configure GPIO pin Output Level */
  HAL_GPIO_WritePin(LD1_GPIO_Port, LD1_Pin, GPIO_PIN_RESET);

  /*Configure GPIO pin Output Level */
  HAL_GPIO_WritePin(LCD_RST_GPIO_Port, LCD_RST_Pin, GPIO_PIN_RESET);

  /*Configure GPIO pins : PI6 PI5 PI4 PI7 */
  GPIO_InitStruct.Pin = GPIO_PIN_6|GPIO_PIN_5|GPIO_PIN_4|GPIO_PIN_7;
  GPIO_InitStruct.Mode = GPIO_MODE_AF_PP;
  GPIO_InitStruct.Pull = GPIO_NOPULL;
  GPIO_InitStruct.Speed = GPIO_SPEED_FREQ_LOW;
  GPIO_InitStruct.Alternate = GPIO_AF10_SAI2;
  HAL_GPIO_Init(GPIOI, &GPIO_InitStruct);

  /*Configure GPIO pins : FDCAN2_RX_Pin FDCAN2_TX_Pin */
  GPIO_InitStruct.Pin = FDCAN2_RX_Pin|FDCAN2_TX_Pin;
  GPIO_InitStruct.Mode = GPIO_MODE_AF_PP;
  GPIO_InitStruct.Pull = GPIO_NOPULL;
  GPIO_InitStruct.Speed = GPIO_SPEED_FREQ_LOW;
  GPIO_InitStruct.Alternate = GPIO_AF9_FDCAN2;
  HAL_GPIO_Init(GPIOB, &GPIO_InitStruct);

  /*Configure GPIO pins : PK5 PK4 PK6 PK3
                           PK7 PK2 */
  GPIO_InitStruct.Pin = GPIO_PIN_5|GPIO_PIN_4|GPIO_PIN_6|GPIO_PIN_3
                          |GPIO_PIN_7|GPIO_PIN_2;
  GPIO_InitStruct.Mode = GPIO_MODE_AF_PP;
  GPIO_InitStruct.Pull = GPIO_NOPULL;
  GPIO_InitStruct.Speed = GPIO_SPEED_FREQ_LOW;
  GPIO_InitStruct.Alternate = GPIO_AF14_LTDC;
  HAL_GPIO_Init(GPIOK, &GPIO_InitStruct);

  /*Configure GPIO pin : PG10 */
  GPIO_InitStruct.Pin = GPIO_PIN_10;
  GPIO_InitStruct.Mode = GPIO_MODE_AF_PP;
  GPIO_InitStruct.Pull = GPIO_NOPULL;
  GPIO_InitStruct.Speed = GPIO_SPEED_FREQ_LOW;
  GPIO_InitStruct.Alternate = GPIO_AF10_SAI2;
  HAL_GPIO_Init(GPIOG, &GPIO_InitStruct);

  /*Configure GPIO pins : SDIO1_D2_Pin SDIO1_D3_Pin SDIO1_CK_Pin SDIO1_D0_Pin
                           SDIO1_D1_Pin SDIO1_D7_Pin SDIO1_D6_Pin */
  GPIO_InitStruct.Pin = SDIO1_D2_Pin|SDIO1_D3_Pin|SDIO1_CK_Pin|SDIO1_D0_Pin
                          |SDIO1_D1_Pin|SDIO1_D7_Pin|SDIO1_D6_Pin;
  GPIO_InitStruct.Mode = GPIO_MODE_AF_PP;
  GPIO_InitStruct.Pull = GPIO_NOPULL;
  GPIO_InitStruct.Speed = GPIO_SPEED_FREQ_VERY_HIGH;
  GPIO_InitStruct.Alternate = GPIO_AF12_SDIO1;
  HAL_GPIO_Init(GPIOC, &GPIO_InitStruct);

  /*Configure GPIO pins : PI1 PI0 PI9 PI12
                           PI14 PI15 */
  GPIO_InitStruct.Pin = GPIO_PIN_1|GPIO_PIN_0|GPIO_PIN_9|GPIO_PIN_12
                          |GPIO_PIN_14|GPIO_PIN_15;
  GPIO_InitStruct.Mode = GPIO_MODE_AF_PP;
  GPIO_InitStruct.Pull = GPIO_NOPULL;
  GPIO_InitStruct.Speed = GPIO_SPEED_FREQ_LOW;
  GPIO_InitStruct.Alternate = GPIO_AF14_LTDC;
  HAL_GPIO_Init(GPIOI, &GPIO_InitStruct);

  /*Configure GPIO pins : PE1 PE0 PE10 PE9
                           PE11 PE12 PE15 PE8
                           PE13 PE7 PE14 */
  GPIO_InitStruct.Pin = GPIO_PIN_1|GPIO_PIN_0|GPIO_PIN_10|GPIO_PIN_9
                          |GPIO_PIN_11|GPIO_PIN_12|GPIO_PIN_15|GPIO_PIN_8
                          |GPIO_PIN_13|GPIO_PIN_7|GPIO_PIN_14;
  GPIO_InitStruct.Mode = GPIO_MODE_AF_PP;
  GPIO_InitStruct.Pull = GPIO_NOPULL;
  GPIO_InitStruct.Speed = GPIO_SPEED_FREQ_VERY_HIGH;
  GPIO_InitStruct.Alternate = GPIO_AF12_FMC;
  HAL_GPIO_Init(GPIOE, &GPIO_InitStruct);

  /*Configure GPIO pin : PB6 */
  GPIO_InitStruct.Pin = GPIO_PIN_6;
  GPIO_InitStruct.Mode = GPIO_MODE_AF_PP;
  GPIO_InitStruct.Pull = GPIO_NOPULL;
  GPIO_InitStruct.Speed = GPIO_SPEED_FREQ_LOW;
  GPIO_InitStruct.Alternate = GPIO_AF10_QUADSPI;
  HAL_GPIO_Init(GPIOB, &GPIO_InitStruct);

  /*Configure GPIO pin : PB4 */
  GPIO_InitStruct.Pin = GPIO_PIN_4;
  GPIO_InitStruct.Mode = GPIO_MODE_AF_PP;
  GPIO_InitStruct.Pull = GPIO_NOPULL;
  GPIO_InitStruct.Speed = GPIO_SPEED_FREQ_LOW;
  GPIO_InitStruct.Alternate = GPIO_AF7_SPI2;
  HAL_GPIO_Init(GPIOB, &GPIO_InitStruct);

  /*Configure GPIO pins : MII_TX_EN_Pin MII_TXD1_Pin MII_TXD0_Pin */
  GPIO_InitStruct.Pin = MII_TX_EN_Pin|MII_TXD1_Pin|MII_TXD0_Pin;
  GPIO_InitStruct.Mode = GPIO_MODE_AF_PP;
  GPIO_InitStruct.Pull = GPIO_NOPULL;
  GPIO_InitStruct.Speed = GPIO_SPEED_FREQ_LOW;
  GPIO_InitStruct.Alternate = GPIO_AF11_ETH;
  HAL_GPIO_Init(GPIOG, &GPIO_InitStruct);

  /*Configure GPIO pins : LCD_DISP_Pin PJ14 PJ12 PJ13
                           PJ11 PJ10 PJ9 PJ0
                           PJ8 PJ7 PJ6 PJ1
                           PJ5 PJ3 PJ4 */
  GPIO_InitStruct.Pin = LCD_DISP_Pin|GPIO_PIN_14|GPIO_PIN_12|GPIO_PIN_13
                          |GPIO_PIN_11|GPIO_PIN_10|GPIO_PIN_9|GPIO_PIN_0
                          |GPIO_PIN_8|GPIO_PIN_7|GPIO_PIN_6|GPIO_PIN_1
                          |GPIO_PIN_5|GPIO_PIN_3|GPIO_PIN_4;
  GPIO_InitStruct.Mode = GPIO_MODE_AF_PP;
  GPIO_InitStruct.Pull = GPIO_NOPULL;
  GPIO_InitStruct.Speed = GPIO_SPEED_FREQ_LOW;
  GPIO_InitStruct.Alternate = GPIO_AF14_LTDC;
  HAL_GPIO_Init(GPIOJ, &GPIO_InitStruct);

  /*Configure GPIO pin : PD3 */
  GPIO_InitStruct.Pin = GPIO_PIN_3;
  GPIO_InitStruct.Mode = GPIO_MODE_AF_PP;
  GPIO_InitStruct.Pull = GPIO_NOPULL;
  GPIO_InitStruct.Speed = GPIO_SPEED_FREQ_LOW;
  GPIO_InitStruct.Alternate = GPIO_AF5_SPI2;
  HAL_GPIO_Init(GPIOD, &GPIO_InitStruct);

  /*Configure GPIO pin : PI2 */
  GPIO_InitStruct.Pin = GPIO_PIN_2;
  GPIO_InitStruct.Mode = GPIO_MODE_AF_PP;
  GPIO_InitStruct.Pull = GPIO_NOPULL;
  GPIO_InitStruct.Speed = GPIO_SPEED_FREQ_LOW;
  GPIO_InitStruct.Alternate = GPIO_AF5_SPI2;
  HAL_GPIO_Init(GPIOI, &GPIO_InitStruct);

  /*Configure GPIO pin : PH15 */
  GPIO_InitStruct.Pin = GPIO_PIN_15;
  GPIO_InitStruct.Mode = GPIO_MODE_AF_PP;
  GPIO_InitStruct.Pull = GPIO_NOPULL;
  GPIO_InitStruct.Speed = GPIO_SPEED_FREQ_LOW;
  GPIO_InitStruct.Alternate = GPIO_AF3_TIM8;
  HAL_GPIO_Init(GPIOH, &GPIO_InitStruct);

  /*Configure GPIO pins : FDCAN1_RX_Pin FDCAN1_TX_Pin */
  GPIO_InitStruct.Pin = FDCAN1_RX_Pin|FDCAN1_TX_Pin;
  GPIO_InitStruct.Mode = GPIO_MODE_AF_PP;
  GPIO_InitStruct.Pull = GPIO_NOPULL;
  GPIO_InitStruct.Speed = GPIO_SPEED_FREQ_LOW;
  GPIO_InitStruct.Alternate = GPIO_AF9_FDCAN1;
  HAL_GPIO_Init(GPIOH, &GPIO_InitStruct);

  /*Configure GPIO pin : MII_TXD3_Pin */
  GPIO_InitStruct.Pin = MII_TXD3_Pin;
  GPIO_InitStruct.Mode = GPIO_MODE_AF_PP;
  GPIO_InitStruct.Pull = GPIO_NOPULL;
  GPIO_InitStruct.Speed = GPIO_SPEED_FREQ_LOW;
  GPIO_InitStruct.Alternate = GPIO_AF11_ETH;
  HAL_GPIO_Init(MII_TXD3_GPIO_Port, &GPIO_InitStruct);

  /*Configure GPIO pin : LCD_DISPD7_Pin */
  GPIO_InitStruct.Pin = LCD_DISPD7_Pin;
  GPIO_InitStruct.Mode = GPIO_MODE_INPUT;
  GPIO_InitStruct.Pull = GPIO_NOPULL;
  HAL_GPIO_Init(LCD_DISPD7_GPIO_Port, &GPIO_InitStruct);

  /*Configure GPIO pins : PE5 PE4 */
  GPIO_InitStruct.Pin = GPIO_PIN_5|GPIO_PIN_4;
  GPIO_InitStruct.Mode = GPIO_MODE_AF_PP;
  GPIO_InitStruct.Pull = GPIO_NOPULL;
  GPIO_InitStruct.Speed = GPIO_SPEED_FREQ_LOW;
  GPIO_InitStruct.Alternate = GPIO_AF10_SAI4;
  HAL_GPIO_Init(GPIOE, &GPIO_InitStruct);

  /*Configure GPIO pins : SDIO1_D5_Pin SDIO1_D4_Pin */
  GPIO_InitStruct.Pin = SDIO1_D5_Pin|SDIO1_D4_Pin;
  GPIO_InitStruct.Mode = GPIO_MODE_AF_PP;
  GPIO_InitStruct.Pull = GPIO_NOPULL;
  GPIO_InitStruct.Speed = GPIO_SPEED_FREQ_VERY_HIGH;
  GPIO_InitStruct.Alternate = GPIO_AF12_SDIO1;
  HAL_GPIO_Init(GPIOB, &GPIO_InitStruct);

  /*Configure GPIO pins : PG15 PG8 PG5 PG4
                           PG0 PG1 */
  GPIO_InitStruct.Pin = GPIO_PIN_15|GPIO_PIN_8|GPIO_PIN_5|GPIO_PIN_4
                          |GPIO_PIN_0|GPIO_PIN_1;
  GPIO_InitStruct.Mode = GPIO_MODE_AF_PP;
  GPIO_InitStruct.Pull = GPIO_NOPULL;
  GPIO_InitStruct.Speed = GPIO_SPEED_FREQ_VERY_HIGH;
  GPIO_InitStruct.Alternate = GPIO_AF12_FMC;
  HAL_GPIO_Init(GPIOG, &GPIO_InitStruct);

  /*Configure GPIO pin : SDIO1_CMD_Pin */
  GPIO_InitStruct.Pin = SDIO1_CMD_Pin;
  GPIO_InitStruct.Mode = GPIO_MODE_AF_PP;
  GPIO_InitStruct.Pull = GPIO_NOPULL;
  GPIO_InitStruct.Speed = GPIO_SPEED_FREQ_VERY_HIGH;
  GPIO_InitStruct.Alternate = GPIO_AF12_SDIO1;
  HAL_GPIO_Init(SDIO1_CMD_GPIO_Port, &GPIO_InitStruct);

  /*Configure GPIO pins : PD0 PD1 PD15 PD14
                           PD10 PD9 PD8 */
  GPIO_InitStruct.Pin = GPIO_PIN_0|GPIO_PIN_1|GPIO_PIN_15|GPIO_PIN_14
                          |GPIO_PIN_10|GPIO_PIN_9|GPIO_PIN_8;
  GPIO_InitStruct.Mode = GPIO_MODE_AF_PP;
  GPIO_InitStruct.Pull = GPIO_NOPULL;
  GPIO_InitStruct.Speed = GPIO_SPEED_FREQ_VERY_HIGH;
  GPIO_InitStruct.Alternate = GPIO_AF12_FMC;
  HAL_GPIO_Init(GPIOD, &GPIO_InitStruct);

  /*Configure GPIO pin : USB_OTG_FS2_ID_Pin */
  GPIO_InitStruct.Pin = USB_OTG_FS2_ID_Pin;
  GPIO_InitStruct.Mode = GPIO_MODE_INPUT;
  GPIO_InitStruct.Pull = GPIO_NOPULL;
  HAL_GPIO_Init(USB_OTG_FS2_ID_GPIO_Port, &GPIO_InitStruct);

  /*Configure GPIO pin : B1_Pin */
  GPIO_InitStruct.Pin = B1_Pin;
  GPIO_InitStruct.Mode = GPIO_MODE_INPUT;
  GPIO_InitStruct.Pull = GPIO_NOPULL;
  HAL_GPIO_Init(B1_GPIO_Port, &GPIO_InitStruct);

  /*Configure GPIO pin : PA8 */
  GPIO_InitStruct.Pin = GPIO_PIN_8;
  GPIO_InitStruct.Mode = GPIO_MODE_AF_PP;
  GPIO_InitStruct.Pull = GPIO_NOPULL;
  GPIO_InitStruct.Speed = GPIO_SPEED_FREQ_LOW;
  GPIO_InitStruct.Alternate = GPIO_AF1_TIM1;
  HAL_GPIO_Init(GPIOA, &GPIO_InitStruct);

  /*Configure GPIO pin : MII_RX_ER_Pin */
  GPIO_InitStruct.Pin = MII_RX_ER_Pin;
  GPIO_InitStruct.Mode = GPIO_MODE_AF_PP;
  GPIO_InitStruct.Pull = GPIO_NOPULL;
  GPIO_InitStruct.Speed = GPIO_SPEED_FREQ_LOW;
  GPIO_InitStruct.Alternate = GPIO_AF11_ETH;
  HAL_GPIO_Init(MII_RX_ER_GPIO_Port, &GPIO_InitStruct);

  /*Configure GPIO pins : PF2 PF1 PF0 PF3
                           PF5 PF4 PF13 PF14
                           PF12 PF15 PF11 */
  GPIO_InitStruct.Pin = GPIO_PIN_2|GPIO_PIN_1|GPIO_PIN_0|GPIO_PIN_3
                          |GPIO_PIN_5|GPIO_PIN_4|GPIO_PIN_13|GPIO_PIN_14
                          |GPIO_PIN_12|GPIO_PIN_15|GPIO_PIN_11;
  GPIO_InitStruct.Mode = GPIO_MODE_AF_PP;
  GPIO_InitStruct.Pull = GPIO_NOPULL;
  GPIO_InitStruct.Speed = GPIO_SPEED_FREQ_VERY_HIGH;
  GPIO_InitStruct.Alternate = GPIO_AF12_FMC;
  HAL_GPIO_Init(GPIOF, &GPIO_InitStruct);

  /*Configure GPIO pin : LD2_Pin */
  GPIO_InitStruct.Pin = LD2_Pin;
  GPIO_InitStruct.Mode = GPIO_MODE_OUTPUT_PP;
  GPIO_InitStruct.Pull = GPIO_NOPULL;
  GPIO_InitStruct.Speed = GPIO_SPEED_FREQ_LOW;
  HAL_GPIO_Init(LD2_GPIO_Port, &GPIO_InitStruct);

  /*Configure GPIO pin : LCD_INT_Pin */
  GPIO_InitStruct.Pin = LCD_INT_Pin;
  GPIO_InitStruct.Mode = GPIO_MODE_IT_RISING;
  GPIO_InitStruct.Pull = GPIO_NOPULL;
  HAL_GPIO_Init(LCD_INT_GPIO_Port, &GPIO_InitStruct);

  /*Configure GPIO pin : LCD_BL_Pin */
  GPIO_InitStruct.Pin = LCD_BL_Pin;
  GPIO_InitStruct.Mode = GPIO_MODE_INPUT;
  GPIO_InitStruct.Pull = GPIO_NOPULL;
  HAL_GPIO_Init(LCD_BL_GPIO_Port, &GPIO_InitStruct);

  /*Configure GPIO pins : PF6 PF7 PF10 */
  GPIO_InitStruct.Pin = GPIO_PIN_6|GPIO_PIN_7|GPIO_PIN_10;
  GPIO_InitStruct.Mode = GPIO_MODE_AF_PP;
  GPIO_InitStruct.Pull = GPIO_NOPULL;
  GPIO_InitStruct.Speed = GPIO_SPEED_FREQ_LOW;
  GPIO_InitStruct.Alternate = GPIO_AF9_QUADSPI;
  HAL_GPIO_Init(GPIOF, &GPIO_InitStruct);

  /*Configure GPIO pin : PC0 */
  GPIO_InitStruct.Pin = GPIO_PIN_0;
  GPIO_InitStruct.Mode = GPIO_MODE_ANALOG;
  GPIO_InitStruct.Pull = GPIO_NOPULL;
  HAL_GPIO_Init(GPIOC, &GPIO_InitStruct);

  /*Configure GPIO pin : PF9 */
  GPIO_InitStruct.Pin = GPIO_PIN_9;
  GPIO_InitStruct.Mode = GPIO_MODE_AF_PP;
  GPIO_InitStruct.Pull = GPIO_NOPULL;
  GPIO_InitStruct.Speed = GPIO_SPEED_FREQ_LOW;
  GPIO_InitStruct.Alternate = GPIO_AF10_QUADSPI;
  HAL_GPIO_Init(GPIOF, &GPIO_InitStruct);

  /*Configure GPIO pins : MII_MDC_Pin MII_TXD2_Pin MII_TX_CLK_Pin MII_RXD0_Pin
                           MII_RXD1_Pin */
  GPIO_InitStruct.Pin = MII_MDC_Pin|MII_TXD2_Pin|MII_TX_CLK_Pin|MII_RXD0_Pin
                          |MII_RXD1_Pin;
  GPIO_InitStruct.Mode = GPIO_MODE_AF_PP;
  GPIO_InitStruct.Pull = GPIO_NOPULL;
  GPIO_InitStruct.Speed = GPIO_SPEED_FREQ_LOW;
  GPIO_InitStruct.Alternate = GPIO_AF11_ETH;
  HAL_GPIO_Init(GPIOC, &GPIO_InitStruct);

  /*Configure GPIO pins : MII_CRS_Pin MII_COL_Pin */
  GPIO_InitStruct.Pin = MII_CRS_Pin|MII_COL_Pin;
  GPIO_InitStruct.Mode = GPIO_MODE_AF_PP;
  GPIO_InitStruct.Pull = GPIO_NOPULL;
  GPIO_InitStruct.Speed = GPIO_SPEED_FREQ_LOW;
  GPIO_InitStruct.Alternate = GPIO_AF11_ETH;
  HAL_GPIO_Init(GPIOH, &GPIO_InitStruct);

  /*Configure GPIO pins : MII_MDIO_Pin MII_RX_CLK_Pin MII_RX_DV_Pin */
  GPIO_InitStruct.Pin = MII_MDIO_Pin|MII_RX_CLK_Pin|MII_RX_DV_Pin;
  GPIO_InitStruct.Mode = GPIO_MODE_AF_PP;
  GPIO_InitStruct.Pull = GPIO_NOPULL;
  GPIO_InitStruct.Speed = GPIO_SPEED_FREQ_LOW;
  GPIO_InitStruct.Alternate = GPIO_AF11_ETH;
  HAL_GPIO_Init(GPIOA, &GPIO_InitStruct);

  /*Configure GPIO pins : PH5 PH6 PH7 */
  GPIO_InitStruct.Pin = GPIO_PIN_5|GPIO_PIN_6|GPIO_PIN_7;
  GPIO_InitStruct.Mode = GPIO_MODE_AF_PP;
  GPIO_InitStruct.Pull = GPIO_NOPULL;
  GPIO_InitStruct.Speed = GPIO_SPEED_FREQ_VERY_HIGH;
  GPIO_InitStruct.Alternate = GPIO_AF12_FMC;
  HAL_GPIO_Init(GPIOH, &GPIO_InitStruct);

  /*Configure GPIO pins : VCP_TX_Pin VCP_RX_Pin */
  GPIO_InitStruct.Pin = VCP_TX_Pin|VCP_RX_Pin;
  GPIO_InitStruct.Mode = GPIO_MODE_AF_PP;
  GPIO_InitStruct.Pull = GPIO_NOPULL;
  GPIO_InitStruct.Speed = GPIO_SPEED_FREQ_LOW;
  GPIO_InitStruct.Alternate = GPIO_AF7_USART3;
  HAL_GPIO_Init(GPIOB, &GPIO_InitStruct);

  /*Configure GPIO pin : OTG_FS2_OverCurrent_Pin */
  GPIO_InitStruct.Pin = OTG_FS2_OverCurrent_Pin;
  GPIO_InitStruct.Mode = GPIO_MODE_IT_RISING;
  GPIO_InitStruct.Pull = GPIO_NOPULL;
  HAL_GPIO_Init(OTG_FS2_OverCurrent_GPIO_Port, &GPIO_InitStruct);

  /*Configure GPIO pin : PA6 */
  GPIO_InitStruct.Pin = GPIO_PIN_6;
  GPIO_InitStruct.Mode = GPIO_MODE_AF_PP;
  GPIO_InitStruct.Pull = GPIO_NOPULL;
  GPIO_InitStruct.Speed = GPIO_SPEED_FREQ_LOW;
  GPIO_InitStruct.Alternate = GPIO_AF9_TIM13;
  HAL_GPIO_Init(GPIOA, &GPIO_InitStruct);

  /*Configure GPIO pin : PH9 */
  GPIO_InitStruct.Pin = GPIO_PIN_9;
  GPIO_InitStruct.Mode = GPIO_MODE_AF_PP;
  GPIO_InitStruct.Pull = GPIO_NOPULL;
  GPIO_InitStruct.Speed = GPIO_SPEED_FREQ_LOW;
  GPIO_InitStruct.Alternate = GPIO_AF14_LTDC;
  HAL_GPIO_Init(GPIOH, &GPIO_InitStruct);

  /*Configure GPIO pin : PD11 */
  GPIO_InitStruct.Pin = GPIO_PIN_11;
  GPIO_InitStruct.Mode = GPIO_MODE_AF_PP;
  GPIO_InitStruct.Pull = GPIO_NOPULL;
  GPIO_InitStruct.Speed = GPIO_SPEED_FREQ_LOW;
  GPIO_InitStruct.Alternate = GPIO_AF9_QUADSPI;
  HAL_GPIO_Init(GPIOD, &GPIO_InitStruct);

  /*Configure GPIO pins : MII_RX_D3_Pin MII_RX_D2_Pin */
  GPIO_InitStruct.Pin = MII_RX_D3_Pin|MII_RX_D2_Pin;
  GPIO_InitStruct.Mode = GPIO_MODE_AF_PP;
  GPIO_InitStruct.Pull = GPIO_NOPULL;
  GPIO_InitStruct.Speed = GPIO_SPEED_FREQ_LOW;
  GPIO_InitStruct.Alternate = GPIO_AF11_ETH;
  HAL_GPIO_Init(GPIOB, &GPIO_InitStruct);

  /*Configure GPIO pin : LD1_Pin */
  GPIO_InitStruct.Pin = LD1_Pin;
  GPIO_InitStruct.Mode = GPIO_MODE_OUTPUT_PP;
  GPIO_InitStruct.Pull = GPIO_NOPULL;
  GPIO_InitStruct.Speed = GPIO_SPEED_FREQ_LOW;
  HAL_GPIO_Init(LD1_GPIO_Port, &GPIO_InitStruct);

  /*Configure GPIO pin : LCD_RST_Pin */
  GPIO_InitStruct.Pin = LCD_RST_Pin;
  GPIO_InitStruct.Mode = GPIO_MODE_OUTPUT_PP;
  GPIO_InitStruct.Pull = GPIO_NOPULL;
  GPIO_InitStruct.Speed = GPIO_SPEED_FREQ_LOW;
  HAL_GPIO_Init(LCD_RST_GPIO_Port, &GPIO_InitStruct);

  /*Configure GPIO pin : PB15 */
  GPIO_InitStruct.Pin = GPIO_PIN_15;
  GPIO_InitStruct.Mode = GPIO_MODE_AF_PP;
  GPIO_InitStruct.Pull = GPIO_NOPULL;
  GPIO_InitStruct.Speed = GPIO_SPEED_FREQ_LOW;
  GPIO_InitStruct.Alternate = GPIO_AF5_SPI2;
  HAL_GPIO_Init(GPIOB, &GPIO_InitStruct);

  /*AnalogSwitch Config */
  HAL_SYSCFG_AnalogSwitchConfig(SYSCFG_SWITCH_PA0, SYSCFG_SWITCH_PA0_OPEN);

  /*AnalogSwitch Config */
  HAL_SYSCFG_AnalogSwitchConfig(SYSCFG_SWITCH_PA1, SYSCFG_SWITCH_PA1_OPEN);

}

/* USER CODE BEGIN 4 */

void FillBuffer(float* buffer, uint32_t size)
{
  uint32_t i = 0;
  uint32_t step = AXIS_NUMBER;

  if(counterOfTestData == 0) {
	  timestamp = htim16.Instance->CNT;
  }

  while (i < size)
  {

	  buffer[0] = testData[counterOfTestData][0];
	  buffer[1] = testData[counterOfTestData][1];
	  buffer[2] = testData[counterOfTestData][2];
	  buffer[3] = testData[counterOfTestData][3];
	  buffer[4] = testData[counterOfTestData][4];
	  buffer[5] = testData[counterOfTestData][5];
	  buffer[6] = testData[counterOfTestData][6];
	  buffer[7] = testData[counterOfTestData][7];
	  buffer[8] = testData[counterOfTestData][8];
	  buffer[9] = testData[counterOfTestData][9];
	  buffer[10] = testData[counterOfTestData][10];
	  buffer[11] = testData[counterOfTestData][11];
	  buffer[12] = testData[counterOfTestData][12];
	  buffer[13] = testData[counterOfTestData][13];
	  buffer[14] = testData[counterOfTestData][14];
	  buffer[15] = testData[counterOfTestData][15];

	  counterOfTestData++;

	  i += step;
  }
}

void Inference(void)
{
  uint16_t id_class;

  FillBuffer(input_user_buffer,SIGNAL_SIZE);
  neai_classification(input_user_buffer,output_class_buffer,&id_class);

  //snprintf(SendBuffer,BUFSIZE,"Class: %s [%u%%]\r\n",id2class[id_class],(uint)(output_class_buffer[id_class-1]*100));
  //CDC_Transmit_FS(SendBuffer,strlen(SendBuffer));

  if(counterOfTestData == sizeOfTestData) {
	  counterOfTestData = 0;

	  uint32_t duration = htim16.Instance->CNT;

	  if(duration >= timestamp)
	  	duration -= timestamp;
	  else
	  	duration += (65535 - timestamp) + 1; //+1 because of counting from 0 onwards

	  //snprintf(SendBuffer,BUFSIZE,"Trajanje izvajanja: %lu milisekund. \r\n", duration);
	  //CDC_Transmit_FS(SendBuffer,strlen(SendBuffer));

	  averageDurationValue += duration;
	  countDurations++;

	  if(countDurations == numberOfDurations) {
	  	snprintf(SendBuffer,BUFSIZE,"Trajanje izvajanja: [%lu] %lu milisekund. \r\n", averageDurationValue, averageDurationValue / 100);
	  	CDC_Transmit_FS(SendBuffer,strlen(SendBuffer));

	  	countDurations = 0;
	  	averageDurationValue = 0;
	  }
  }

}

/* USER CODE END 4 */

void Error_Handler(void)
{
  __disable_irq();
  while (1)
  {
  }
}
